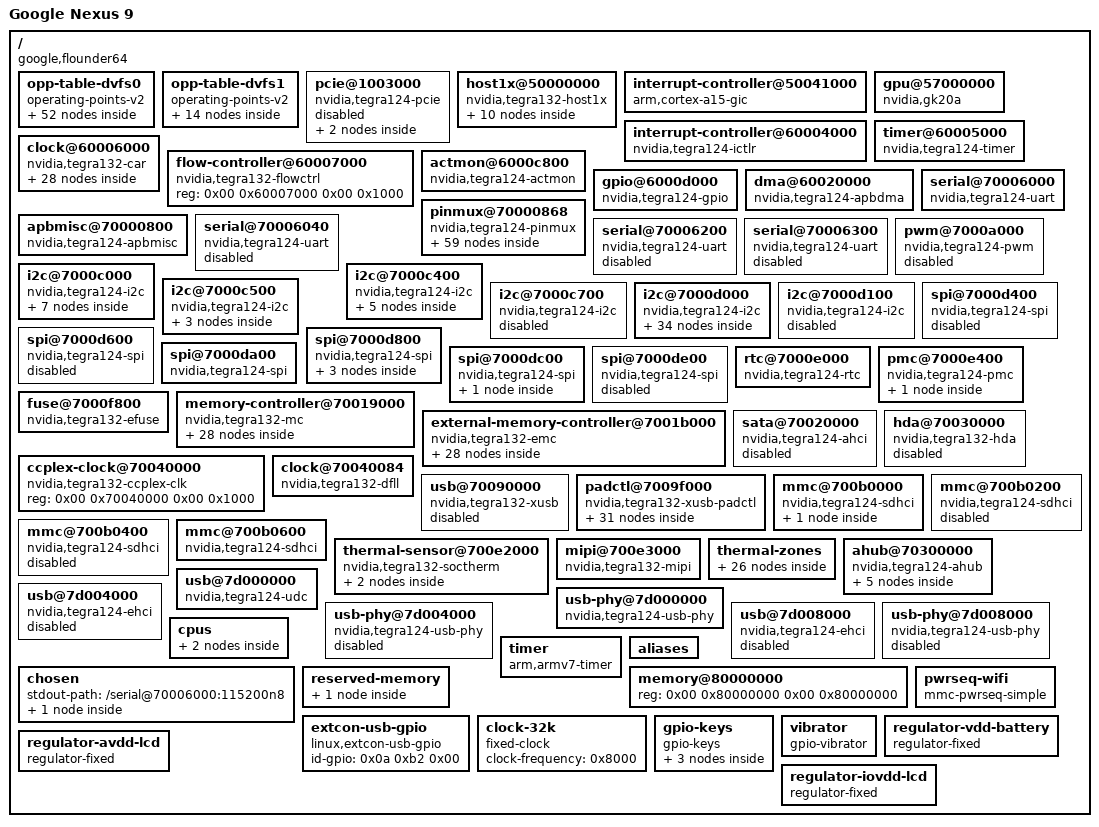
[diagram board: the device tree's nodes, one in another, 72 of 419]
/dts-v1/;

/ {
	compatible = "google,flounder64", "nvidia,tegra132";
	interrupt-parent = <0x01>;
	#address-cells = <0x02>;
	#size-cells = <0x02>;
	model = "Google Nexus 9";

	opp-table-dvfs0 {
		compatible = "operating-points-v2";
		phandle = <0x1a>;

		opp-12750000-800 {
			opp-microvolt = <0xc3500 0xc3500 0x118c30>;
			opp-hz = <0x00 0xc28cb0>;
			opp-supported-hw = <0x03>;
		};

		opp-12750000-950 {
			opp-microvolt = <0xe7ef0 0xe7ef0 0x118c30>;
			opp-hz = <0x00 0xc28cb0>;
			opp-supported-hw = <0x08>;
		};

		opp-12750000-1050 {
			opp-microvolt = <0x100590 0x100590 0x118c30>;
			opp-hz = <0x00 0xc28cb0>;
			opp-supported-hw = <0x10>;
		};

		opp-12750000-1110 {
			opp-microvolt = <0x10eff0 0x10eff0 0x118c30>;
			opp-hz = <0x00 0xc28cb0>;
			opp-supported-hw = <0x04>;
		};

		opp-20400000-800 {
			opp-microvolt = <0xc3500 0xc3500 0x118c30>;
			opp-hz = <0x00 0x1374780>;
			opp-supported-hw = <0x03>;
		};

		opp-20400000-950 {
			opp-microvolt = <0xe7ef0 0xe7ef0 0x118c30>;
			opp-hz = <0x00 0x1374780>;
			opp-supported-hw = <0x08>;
		};

		opp-20400000-1050 {
			opp-microvolt = <0x100590 0x100590 0x118c30>;
			opp-hz = <0x00 0x1374780>;
			opp-supported-hw = <0x10>;
		};

		opp-20400000-1110 {
			opp-microvolt = <0x10eff0 0x10eff0 0x118c30>;
			opp-hz = <0x00 0x1374780>;
			opp-supported-hw = <0x04>;
		};

		opp-40800000-800 {
			opp-microvolt = <0xc3500 0xc3500 0x118c30>;
			opp-hz = <0x00 0x26e8f00>;
			opp-supported-hw = <0x03>;
		};

		opp-40800000-950 {
			opp-microvolt = <0xe7ef0 0xe7ef0 0x118c30>;
			opp-hz = <0x00 0x26e8f00>;
			opp-supported-hw = <0x08>;
		};

		opp-40800000-1050 {
			opp-microvolt = <0x100590 0x100590 0x118c30>;
			opp-hz = <0x00 0x26e8f00>;
			opp-supported-hw = <0x10>;
		};

		opp-40800000-1110 {
			opp-microvolt = <0x10eff0 0x10eff0 0x118c30>;
			opp-hz = <0x00 0x26e8f00>;
			opp-supported-hw = <0x04>;
		};

		opp-68000000-800 {
			opp-microvolt = <0xc3500 0xc3500 0x118c30>;
			opp-hz = <0x00 0x40d9900>;
			opp-supported-hw = <0x03>;
		};

		opp-68000000-950 {
			opp-microvolt = <0xe7ef0 0xe7ef0 0x118c30>;
			opp-hz = <0x00 0x40d9900>;
			opp-supported-hw = <0x08>;
		};

		opp-68000000-1050 {
			opp-microvolt = <0x100590 0x100590 0x118c30>;
			opp-hz = <0x00 0x40d9900>;
			opp-supported-hw = <0x10>;
		};

		opp-68000000-1110 {
			opp-microvolt = <0x10eff0 0x10eff0 0x118c30>;
			opp-hz = <0x00 0x40d9900>;
			opp-supported-hw = <0x04>;
		};

		opp-102000000-800 {
			opp-microvolt = <0xc3500 0xc3500 0x118c30>;
			opp-hz = <0x00 0x6146580>;
			opp-supported-hw = <0x03>;
		};

		opp-102000000-950 {
			opp-microvolt = <0xe7ef0 0xe7ef0 0x118c30>;
			opp-hz = <0x00 0x6146580>;
			opp-supported-hw = <0x08>;
		};

		opp-102000000-1050 {
			opp-microvolt = <0x100590 0x100590 0x118c30>;
			opp-hz = <0x00 0x6146580>;
			opp-supported-hw = <0x10>;
		};

		opp-102000000-1110 {
			opp-microvolt = <0x10eff0 0x10eff0 0x118c30>;
			opp-hz = <0x00 0x6146580>;
			opp-supported-hw = <0x04>;
		};

		opp-204000000-800 {
			opp-microvolt = <0xc3500 0xc3500 0x118c30>;
			opp-hz = <0x00 0xc28cb00>;
			opp-supported-hw = <0x03>;
			opp-suspend;
		};

		opp-204000000-950 {
			opp-microvolt = <0xe7ef0 0xe7ef0 0x118c30>;
			opp-hz = <0x00 0xc28cb00>;
			opp-supported-hw = <0x08>;
			opp-suspend;
		};

		opp-204000000-1050 {
			opp-microvolt = <0x100590 0x100590 0x118c30>;
			opp-hz = <0x00 0xc28cb00>;
			opp-supported-hw = <0x10>;
			opp-suspend;
		};

		opp-204000000-1110 {
			opp-microvolt = <0x10eff0 0x10eff0 0x118c30>;
			opp-hz = <0x00 0xc28cb00>;
			opp-supported-hw = <0x04>;
			opp-suspend;
		};

		opp-264000000-800 {
			opp-microvolt = <0xc3500 0xc3500 0x118c30>;
			opp-hz = <0x00 0xfbc5200>;
			opp-supported-hw = <0x03>;
		};

		opp-264000000-950 {
			opp-microvolt = <0xe7ef0 0xe7ef0 0x118c30>;
			opp-hz = <0x00 0xfbc5200>;
			opp-supported-hw = <0x08>;
		};

		opp-264000000-1050 {
			opp-microvolt = <0x100590 0x100590 0x118c30>;
			opp-hz = <0x00 0xfbc5200>;
			opp-supported-hw = <0x10>;
		};

		opp-264000000-1110 {
			opp-microvolt = <0x10eff0 0x10eff0 0x118c30>;
			opp-hz = <0x00 0xfbc5200>;
			opp-supported-hw = <0x04>;
		};

		opp-300000000-850 {
			opp-microvolt = <0xcf850 0xcf850 0x118c30>;
			opp-hz = <0x00 0x11e1a300>;
			opp-supported-hw = <0x03>;
		};

		opp-300000000-950 {
			opp-microvolt = <0xe7ef0 0xe7ef0 0x118c30>;
			opp-hz = <0x00 0x11e1a300>;
			opp-supported-hw = <0x08>;
		};

		opp-300000000-1050 {
			opp-microvolt = <0x100590 0x100590 0x118c30>;
			opp-hz = <0x00 0x11e1a300>;
			opp-supported-hw = <0x10>;
		};

		opp-300000000-1110 {
			opp-microvolt = <0x10eff0 0x10eff0 0x118c30>;
			opp-hz = <0x00 0x11e1a300>;
			opp-supported-hw = <0x04>;
		};

		opp-348000000-850 {
			opp-microvolt = <0xcf850 0xcf850 0x118c30>;
			opp-hz = <0x00 0x14be0f00>;
			opp-supported-hw = <0x03>;
		};

		opp-348000000-950 {
			opp-microvolt = <0xe7ef0 0xe7ef0 0x118c30>;
			opp-hz = <0x00 0x14be0f00>;
			opp-supported-hw = <0x08>;
		};

		opp-348000000-1050 {
			opp-microvolt = <0x100590 0x100590 0x118c30>;
			opp-hz = <0x00 0x14be0f00>;
			opp-supported-hw = <0x10>;
		};

		opp-348000000-1110 {
			opp-microvolt = <0x10eff0 0x10eff0 0x118c30>;
			opp-hz = <0x00 0x14be0f00>;
			opp-supported-hw = <0x04>;
		};

		opp-396000000-950 {
			opp-microvolt = <0xe7ef0 0xe7ef0 0x118c30>;
			opp-hz = <0x00 0x179a7b00>;
			opp-supported-hw = <0x08>;
		};

		opp-396000000-1000 {
			opp-microvolt = <0xf4240 0xf4240 0x118c30>;
			opp-hz = <0x00 0x179a7b00>;
			opp-supported-hw = <0x03>;
		};

		opp-396000000-1050 {
			opp-microvolt = <0x100590 0x100590 0x118c30>;
			opp-hz = <0x00 0x179a7b00>;
			opp-supported-hw = <0x10>;
		};

		opp-396000000-1110 {
			opp-microvolt = <0x10eff0 0x10eff0 0x118c30>;
			opp-hz = <0x00 0x179a7b00>;
			opp-supported-hw = <0x04>;
		};

		opp-528000000-950 {
			opp-microvolt = <0xe7ef0 0xe7ef0 0x118c30>;
			opp-hz = <0x00 0x1f78a400>;
			opp-supported-hw = <0x08>;
		};

		opp-528000000-1000 {
			opp-microvolt = <0xf4240 0xf4240 0x118c30>;
			opp-hz = <0x00 0x1f78a400>;
			opp-supported-hw = <0x03>;
		};

		opp-528000000-1050 {
			opp-microvolt = <0x100590 0x100590 0x118c30>;
			opp-hz = <0x00 0x1f78a400>;
			opp-supported-hw = <0x10>;
		};

		opp-528000000-1110 {
			opp-microvolt = <0x10eff0 0x10eff0 0x118c30>;
			opp-hz = <0x00 0x1f78a400>;
			opp-supported-hw = <0x04>;
		};

		opp-600000000-950 {
			opp-microvolt = <0xe7ef0 0xe7ef0 0x118c30>;
			opp-hz = <0x00 0x23c34600>;
			opp-supported-hw = <0x08>;
		};

		opp-600000000-1000 {
			opp-microvolt = <0xf4240 0xf4240 0x118c30>;
			opp-hz = <0x00 0x23c34600>;
			opp-supported-hw = <0x03>;
		};

		opp-600000000-1050 {
			opp-microvolt = <0x100590 0x100590 0x118c30>;
			opp-hz = <0x00 0x23c34600>;
			opp-supported-hw = <0x10>;
		};

		opp-600000000-1110 {
			opp-microvolt = <0x10eff0 0x10eff0 0x118c30>;
			opp-hz = <0x00 0x23c34600>;
			opp-supported-hw = <0x04>;
		};

		opp-792000000-1000 {
			opp-microvolt = <0xf4240 0xf4240 0x118c30>;
			opp-hz = <0x00 0x2f34f600>;
			opp-supported-hw = <0x0b>;
		};

		opp-792000000-1050 {
			opp-microvolt = <0x100590 0x100590 0x118c30>;
			opp-hz = <0x00 0x2f34f600>;
			opp-supported-hw = <0x10>;
		};

		opp-792000000-1110 {
			opp-microvolt = <0x10eff0 0x10eff0 0x118c30>;
			opp-hz = <0x00 0x2f34f600>;
			opp-supported-hw = <0x04>;
		};

		opp-924000000-1100 {
			opp-microvolt = <0x10c8e0 0x10c8e0 0x118c30>;
			opp-hz = <0x00 0x37131f00>;
			opp-supported-hw = <0x13>;
		};
	};

	opp-table-dvfs1 {
		compatible = "operating-points-v2";
		phandle = <0x0f>;

		opp-12750000 {
			opp-hz = <0x00 0xc28cb0>;
			opp-supported-hw = <0x1f>;
			opp-peak-kBps = <0x31ce0>;
		};

		opp-20400000 {
			opp-hz = <0x00 0x1374780>;
			opp-supported-hw = <0x1f>;
			opp-peak-kBps = <0x4fb00>;
		};

		opp-40800000 {
			opp-hz = <0x00 0x26e8f00>;
			opp-supported-hw = <0x1f>;
			opp-peak-kBps = <0x9f600>;
		};

		opp-68000000 {
			opp-hz = <0x00 0x40d9900>;
			opp-supported-hw = <0x1f>;
			opp-peak-kBps = <0x109a00>;
		};

		opp-102000000 {
			opp-hz = <0x00 0x6146580>;
			opp-supported-hw = <0x1f>;
			opp-peak-kBps = <0x18e700>;
		};

		opp-204000000 {
			opp-hz = <0x00 0xc28cb00>;
			opp-supported-hw = <0x1f>;
			opp-peak-kBps = <0x31ce00>;
			opp-suspend;
		};

		opp-264000000 {
			opp-hz = <0x00 0xfbc5200>;
			opp-supported-hw = <0x1f>;
			opp-peak-kBps = "", "@t";
		};

		opp-300000000 {
			opp-hz = <0x00 0x11e1a300>;
			opp-supported-hw = <0x1f>;
			opp-peak-kBps = "", "I>";
		};

		opp-348000000 {
			opp-hz = <0x00 0x14be0f00>;
			opp-supported-hw = <0x1f>;
			opp-peak-kBps = <0x54f600>;
		};

		opp-396000000 {
			opp-hz = <0x00 0x179a7b00>;
			opp-supported-hw = <0x1f>;
			opp-peak-kBps = <0x60ae00>;
		};

		opp-528000000 {
			opp-hz = <0x00 0x1f78a400>;
			opp-supported-hw = <0x1f>;
			opp-peak-kBps = <0x80e800>;
		};

		opp-600000000 {
			opp-hz = <0x00 0x23c34600>;
			opp-supported-hw = <0x1f>;
			opp-peak-kBps = <0x927c00>;
		};

		opp-792000000 {
			opp-hz = <0x00 0x2f34f600>;
			opp-supported-hw = <0x1f>;
			opp-peak-kBps = <0xc15c00>;
		};

		opp-924000000 {
			opp-hz = <0x00 0x37131f00>;
			opp-supported-hw = <0x13>;
			opp-peak-kBps = <0xe19600>;
		};
	};

	pcie@1003000 {
		compatible = "nvidia,tegra124-pcie";
		device_type = "pci";
		reg = <0x00 0x1003000 0x00 0x800 0x00 0x1003800 0x00 0x800 0x00 0x2000000 0x00 0x10000000>;
		reg-names = "pads", "afi", "cs";
		interrupts = <0x00 0x62 0x04 0x00 0x63 0x04>;
		interrupt-names = "intr", "msi";
		#interrupt-cells = <0x01>;
		interrupt-map-mask = <0x00 0x00 0x00 0x00>;
		interrupt-map = <0x00 0x00 0x00 0x00 0x02 0x00 0x62 0x04>;
		bus-range = <0x00 0xff>;
		#address-cells = <0x03>;
		#size-cells = <0x02>;
		ranges = <0x2000000 0x00 0x1000000 0x00 0x1000000 0x00 0x1000 0x2000000 0x00 0x1001000 0x00 0x1001000 0x00 0x1000 0x1000000 0x00 0x00 0x00 0x12000000 0x00 0x10000 0x2000000 0x00 0x13000000 0x00 0x13000000 0x00 0xd000000 0x42000000 0x00 0x20000000 0x00 0x20000000 0x00 0x20000000>;
		clocks = <0x03 0x46 0x03 0x48 0x03 0xe7 0x03 0x10c>;
		clock-names = "pex", "afi", "pll_e", "cml";
		resets = <0x03 0x46 0x03 0x48 0x03 0x4a>;
		reset-names = "pex", "afi", "pcie_x";
		status = "disabled";

		pci@1,0 {
			device_type = "pci";
			assigned-addresses = <0x82000800 0x00 0x1000000 0x00 0x1000>;
			reg = <0x800 0x00 0x00 0x00 0x00>;
			bus-range = <0x00 0xff>;
			status = "disabled";
			#address-cells = <0x03>;
			#size-cells = <0x02>;
			ranges;
			nvidia,num-lanes = <0x02>;
		};

		pci@2,0 {
			device_type = "pci";
			assigned-addresses = <0x82001000 0x00 0x1001000 0x00 0x1000>;
			reg = <0x1000 0x00 0x00 0x00 0x00>;
			bus-range = <0x00 0xff>;
			status = "disabled";
			#address-cells = <0x03>;
			#size-cells = <0x02>;
			ranges;
			nvidia,num-lanes = <0x01>;
		};
	};

	host1x@50000000 {
		compatible = "nvidia,tegra132-host1x", "nvidia,tegra124-host1x";
		reg = <0x00 0x50000000 0x00 0x34000>;
		interrupts = <0x00 0x41 0x04 0x00 0x43 0x04>;
		interrupt-names = "syncpt", "host1x";
		clocks = <0x03 0x1c>;
		clock-names = "host1x";
		resets = <0x03 0x1c>;
		reset-names = "host1x";
		#address-cells = <0x02>;
		#size-cells = <0x02>;
		ranges = <0x00 0x54000000 0x00 0x54000000 0x00 0x1000000>;

		dc@54200000 {
			compatible = "nvidia,tegra124-dc";
			reg = <0x00 0x54200000 0x00 0x40000>;
			interrupts = <0x00 0x49 0x04>;
			clocks = <0x03 0x1b>;
			clock-names = "dc";
			resets = <0x03 0x1b>;
			reset-names = "dc";
			iommus = <0x04 0x01>;
			nvidia,head = <0x00>;
		};

		dc@54240000 {
			compatible = "nvidia,tegra124-dc";
			reg = <0x00 0x54240000 0x00 0x40000>;
			interrupts = <0x00 0x4a 0x04>;
			clocks = <0x03 0x1a>;
			clock-names = "dc";
			resets = <0x03 0x1a>;
			reset-names = "dc";
			iommus = <0x04 0x02>;
			nvidia,head = <0x01>;
		};

		hdmi@54280000 {
			compatible = "nvidia,tegra124-hdmi";
			reg = <0x00 0x54280000 0x00 0x40000>;
			interrupts = <0x00 0x4b 0x04>;
			clocks = <0x03 0x33 0x03 0xdd>;
			clock-names = "hdmi", "parent";
			resets = <0x03 0x33>;
			reset-names = "hdmi";
			status = "disabled";
		};

		dsi@54300000 {
			compatible = "nvidia,tegra132-dsi";
			reg = <0x00 0x54300000 0x00 0x40000>;
			clocks = <0x03 0x30 0x03 0x93 0x03 0xdb>;
			clock-names = "dsi", "lp", "parent";
			resets = <0x03 0x30>;
			reset-names = "dsi";
			nvidia,mipi-calibrate = <0x05 0x60>;
			status = "okay";
			#address-cells = <0x01>;
			#size-cells = <0x00>;
			avdd-dsi-csi-supply = <0x06>;
			nvidia,ganged-mode = <0x07>;

			panel@0 {
				compatible = "jdi,lpm089a128a";
				reg = <0x00>;
				avdd-supply = <0x08>;
				iovdd-supply = <0x09>;
				reset-gpios = <0x0a 0x3d 0x00>;
				dcdc-en-gpios = <0x0a 0xf5 0x00>;
				port_b = <0x0b>;
				phandle = <0x0c>;
			};
		};

		dsi@54400000 {
			compatible = "nvidia,tegra132-dsi";
			reg = <0x00 0x54400000 0x00 0x40000>;
			clocks = <0x03 0x52 0x03 0x94 0x03 0xdb>;
			clock-names = "dsi", "lp", "parent";
			resets = <0x03 0x52>;
			reset-names = "dsi";
			nvidia,mipi-calibrate = <0x05 0x180>;
			status = "okay";
			#address-cells = <0x01>;
			#size-cells = <0x00>;
			avdd-dsi-csi-supply = <0x06>;
			phandle = <0x07>;

			panel@0 {
				compatible = "jdi,lpm089a128a";
				reg = <0x00>;
				port_a = <0x0c>;
				phandle = <0x0b>;
			};
		};

		sor@54540000 {
			compatible = "nvidia,tegra124-sor";
			reg = <0x00 0x54540000 0x00 0x40000>;
			interrupts = <0x00 0x4c 0x04>;
			clocks = <0x03 0xb6 0x03 0x137 0x03 0xdb 0x03 0x10f 0x03 0xc9>;
			clock-names = "sor", "out", "parent", "dp", "safe";
			resets = <0x03 0xb6>;
			reset-names = "sor";
			status = "disabled";
		};

		dpaux@545c0000 {
			compatible = "nvidia,tegra124-dpaux";
			reg = <0x00 0x545c0000 0x00 0x40000>;
			interrupts = <0x00 0x9f 0x04>;
			clocks = <0x03 0xb5 0x03 0x10f>;
			clock-names = "dpaux", "parent";
			resets = <0x03 0xb5>;
			reset-names = "dpaux";
			status = "disabled";

			i2c-bus {
				#address-cells = <0x01>;
				#size-cells = <0x00>;
			};
		};
	};

	interrupt-controller@50041000 {
		compatible = "arm,cortex-a15-gic";
		#interrupt-cells = <0x03>;
		interrupt-controller;
		reg = <0x00 0x50041000 0x00 0x1000 0x00 0x50042000 0x00 0x2000 0x00 0x50044000 0x00 0x2000 0x00 0x50046000 0x00 0x2000>;
		interrupts = <0x01 0x09 0xf04>;
		interrupt-parent = <0x02>;
		phandle = <0x02>;
	};

	gpu@57000000 {
		compatible = "nvidia,gk20a";
		reg = <0x00 0x57000000 0x00 0x1000000 0x00 0x58000000 0x00 0x1000000>;
		interrupts = <0x00 0x9d 0x04 0x00 0x9e 0x04>;
		interrupt-names = "stall", "nonstall";
		clocks = <0x03 0xb8 0x03 0x10b>;
		clock-names = "gpu", "pwr";
		resets = <0x03 0xb8>;
		reset-names = "gpu";
		status = "okay";
		vdd-supply = <0x0d>;
	};

	interrupt-controller@60004000 {
		compatible = "nvidia,tegra124-ictlr", "nvidia,tegra30-ictlr";
		reg = <0x00 0x60004000 0x00 0x100 0x00 0x60004100 0x00 0x100 0x00 0x60004200 0x00 0x100 0x00 0x60004300 0x00 0x100 0x00 0x60004400 0x00 0x100>;
		interrupt-controller;
		#interrupt-cells = <0x03>;
		interrupt-parent = <0x02>;
		phandle = <0x01>;
	};

	timer@60005000 {
		compatible = "nvidia,tegra124-timer", "nvidia,tegra30-timer";
		reg = <0x00 0x60005000 0x00 0x400>;
		interrupts = <0x00 0x00 0x04 0x00 0x01 0x04 0x00 0x29 0x04 0x00 0x2a 0x04 0x00 0x79 0x04 0x00 0x7a 0x04>;
		clocks = <0x03 0x05>;
		clock-names = "timer";
	};

	clock@60006000 {
		compatible = "nvidia,tegra132-car";
		reg = <0x00 0x60006000 0x00 0x1000>;
		#clock-cells = <0x01>;
		#reset-cells = <0x01>;
		nvidia,external-memory-controller = <0x0e>;
		phandle = <0x03>;

		emc-timings-1 {
			nvidia,ram-code = <0x01>;

			timing-12750000 {
				clock-frequency = <0xc28cb0>;
				nvidia,parent-clock-frequency = <0x18519600>;
				clocks = <0x03 0xd3>;
				clock-names = "emc-parent";
			};

			timing-20400000 {
				clock-frequency = <0x1374780>;
				nvidia,parent-clock-frequency = <0x18519600>;
				clocks = <0x03 0xd3>;
				clock-names = "emc-parent";
			};

			timing-40800000 {
				clock-frequency = <0x26e8f00>;
				nvidia,parent-clock-frequency = <0x18519600>;
				clocks = <0x03 0xd3>;
				clock-names = "emc-parent";
			};

			timing-68000000 {
				clock-frequency = <0x40d9900>;
				nvidia,parent-clock-frequency = <0x18519600>;
				clocks = <0x03 0xd3>;
				clock-names = "emc-parent";
			};

			timing-102000000 {
				clock-frequency = <0x6146580>;
				nvidia,parent-clock-frequency = <0x18519600>;
				clocks = <0x03 0xd3>;
				clock-names = "emc-parent";
			};

			timing-136000000 {
				clock-frequency = <0x81b3200>;
				nvidia,parent-clock-frequency = <0x18519600>;
				clocks = <0x03 0xd3>;
				clock-names = "emc-parent";
			};

			timing-204000000 {
				clock-frequency = <0xc28cb00>;
				nvidia,parent-clock-frequency = <0x18519600>;
				clocks = <0x03 0xd3>;
				clock-names = "emc-parent";
			};

			timing-300000000 {
				clock-frequency = <0x11e1a300>;
				nvidia,parent-clock-frequency = <0x23c34600>;
				clocks = <0x03 0xcd>;
				clock-names = "emc-parent";
			};

			timing-396000000 {
				clock-frequency = <0x179a7b00>;
				nvidia,parent-clock-frequency = <0x2f34f600>;
				clocks = <0x03 0xd1>;
				clock-names = "emc-parent";
			};

			timing-528000000 {
				clock-frequency = <0x1f78a400>;
				nvidia,parent-clock-frequency = <0x1f78a400>;
				clocks = <0x03 0x139>;
				clock-names = "emc-parent";
			};

			timing-600000000 {
				clock-frequency = <0x23c34600>;
				nvidia,parent-clock-frequency = <0x23c34600>;
				clocks = <0x03 0x13a>;
				clock-names = "emc-parent";
			};

			timing-792000000 {
				clock-frequency = <0x2f34f600>;
				nvidia,parent-clock-frequency = <0x2f34f600>;
				clocks = <0x03 0x139>;
				clock-names = "emc-parent";
			};

			timing-924000000 {
				clock-frequency = <0x37131f00>;
				nvidia,parent-clock-frequency = <0x37131f00>;
				clocks = <0x03 0x139>;
				clock-names = "emc-parent";
			};
		};

		emc-timings-2 {
			nvidia,ram-code = <0x02>;

			timing-12750000 {
				clock-frequency = <0xc28cb0>;
				nvidia,parent-clock-frequency = <0x18519600>;
				clocks = <0x03 0xd3>;
				clock-names = "emc-parent";
			};

			timing-20400000 {
				clock-frequency = <0x1374780>;
				nvidia,parent-clock-frequency = <0x18519600>;
				clocks = <0x03 0xd3>;
				clock-names = "emc-parent";
			};

			timing-40800000 {
				clock-frequency = <0x26e8f00>;
				nvidia,parent-clock-frequency = <0x18519600>;
				clocks = <0x03 0xd3>;
				clock-names = "emc-parent";
			};

			timing-68000000 {
				clock-frequency = <0x40d9900>;
				nvidia,parent-clock-frequency = <0x18519600>;
				clocks = <0x03 0xd3>;
				clock-names = "emc-parent";
			};

			timing-102000000 {
				clock-frequency = <0x6146580>;
				nvidia,parent-clock-frequency = <0x18519600>;
				clocks = <0x03 0xd3>;
				clock-names = "emc-parent";
			};

			timing-136000000 {
				clock-frequency = <0x81b3200>;
				nvidia,parent-clock-frequency = <0x18519600>;
				clocks = <0x03 0xd3>;
				clock-names = "emc-parent";
			};

			timing-204000000 {
				clock-frequency = <0xc28cb00>;
				nvidia,parent-clock-frequency = <0x18519600>;
				clocks = <0x03 0xd3>;
				clock-names = "emc-parent";
			};

			timing-300000000 {
				clock-frequency = <0x11e1a300>;
				nvidia,parent-clock-frequency = <0x23c34600>;
				clocks = <0x03 0xcd>;
				clock-names = "emc-parent";
			};

			timing-396000000 {
				clock-frequency = <0x179a7b00>;
				nvidia,parent-clock-frequency = <0x2f34f600>;
				clocks = <0x03 0xd1>;
				clock-names = "emc-parent";
			};

			timing-528000000 {
				clock-frequency = <0x1f78a400>;
				nvidia,parent-clock-frequency = <0x1f78a400>;
				clocks = <0x03 0x139>;
				clock-names = "emc-parent";
			};

			timing-600000000 {
				clock-frequency = <0x23c34600>;
				nvidia,parent-clock-frequency = <0x23c34600>;
				clocks = <0x03 0x13a>;
				clock-names = "emc-parent";
			};

			timing-792000000 {
				clock-frequency = <0x2f34f600>;
				nvidia,parent-clock-frequency = <0x2f34f600>;
				clocks = <0x03 0x139>;
				clock-names = "emc-parent";
			};

			timing-924000000 {
				clock-frequency = <0x37131f00>;
				nvidia,parent-clock-frequency = <0x37131f00>;
				clocks = <0x03 0x139>;
				clock-names = "emc-parent";
			};
		};
	};

	flow-controller@60007000 {
		compatible = "nvidia,tegra132-flowctrl", "nvidia,tegra124-flowctrl";
		reg = <0x00 0x60007000 0x00 0x1000>;
	};

	actmon@6000c800 {
		compatible = "nvidia,tegra124-actmon";
		reg = <0x00 0x6000c800 0x00 0x400>;
		interrupts = <0x00 0x2d 0x04>;
		clocks = <0x03 0x77 0x03 0x39>;
		clock-names = "actmon", "emc";
		resets = <0x03 0x77>;
		reset-names = "actmon";
		operating-points-v2 = <0x0f>;
		interconnects = <0x04 0x27 0x0e>;
		interconnect-names = "cpu-read";
		#cooling-cells = <0x02>;
	};

	gpio@6000d000 {
		compatible = "nvidia,tegra124-gpio", "nvidia,tegra30-gpio";
		reg = <0x00 0x6000d000 0x00 0x1000>;
		interrupts = <0x00 0x20 0x04 0x00 0x21 0x04 0x00 0x22 0x04 0x00 0x23 0x04 0x00 0x37 0x04 0x00 0x57 0x04 0x00 0x59 0x04 0x00 0x7d 0x04>;
		#gpio-cells = <0x02>;
		gpio-controller;
		#interrupt-cells = <0x02>;
		interrupt-controller;
		phandle = <0x0a>;
	};

	dma@60020000 {
		compatible = "nvidia,tegra124-apbdma", "nvidia,tegra148-apbdma";
		reg = <0x00 0x60020000 0x00 0x1400>;
		interrupts = <0x00 0x68 0x04 0x00 0x69 0x04 0x00 0x6a 0x04 0x00 0x6b 0x04 0x00 0x6c 0x04 0x00 0x6d 0x04 0x00 0x6e 0x04 0x00 0x6f 0x04 0x00 0x70 0x04 0x00 0x71 0x04 0x00 0x72 0x04 0x00 0x73 0x04 0x00 0x74 0x04 0x00 0x75 0x04 0x00 0x76 0x04 0x00 0x77 0x04 0x00 0x80 0x04 0x00 0x81 0x04 0x00 0x82 0x04 0x00 0x83 0x04 0x00 0x84 0x04 0x00 0x85 0x04 0x00 0x86 0x04 0x00 0x87 0x04 0x00 0x88 0x04 0x00 0x89 0x04 0x00 0x8a 0x04 0x00 0x8b 0x04 0x00 0x8c 0x04 0x00 0x8d 0x04 0x00 0x8e 0x04 0x00 0x8f 0x04>;
		clocks = <0x03 0x22>;
		clock-names = "dma";
		resets = <0x03 0x22>;
		reset-names = "dma";
		#dma-cells = <0x01>;
		phandle = <0x11>;
	};

	apbmisc@70000800 {
		compatible = "nvidia,tegra124-apbmisc", "nvidia,tegra20-apbmisc";
		reg = <0x00 0x70000800 0x00 0x64 0x00 0x7000e864 0x00 0x04>;
		nvidia,long-ram-code;
	};

	pinmux@70000868 {
		compatible = "nvidia,tegra124-pinmux";
		reg = <0x00 0x70000868 0x00 0x164 0x00 0x70003000 0x00 0x434 0x00 0x70000820 0x00 0x08>;
		pinctrl-names = "default";
		pinctrl-0 = <0x10>;

		pinmux {
			phandle = <0x10>;

			pu0 {
				nvidia,pins = "pu0";
				nvidia,function = "uarta";
				nvidia,pull = <0x00>;
				nvidia,tristate = <0x00>;
				nvidia,enable-input = <0x00>;
			};

			pu1 {
				nvidia,pins = "pu1";
				nvidia,function = "uarta";
				nvidia,pull = <0x02>;
				nvidia,tristate = <0x00>;
				nvidia,enable-input = <0x01>;
			};

			uart3_cts_n_pa1 {
				nvidia,pins = "uart3_cts_n_pa1", "uart3_rxd_pw7";
				nvidia,function = "uartc";
				nvidia,pull = <0x02>;
				nvidia,tristate = <0x00>;
				nvidia,enable-input = <0x01>;
			};

			uart3_rts_n_pc0 {
				nvidia,pins = "uart3_rts_n_pc0", "uart3_txd_pw6";
				nvidia,function = "uartc";
				nvidia,pull = <0x00>;
				nvidia,tristate = <0x00>;
				nvidia,enable-input = <0x00>;
			};

			pj7 {
				nvidia,pins = "pj7";
				nvidia,function = "uartd";
				nvidia,pull = <0x00>;
				nvidia,tristate = <0x00>;
				nvidia,enable-input = <0x00>;
			};

			pb0 {
				nvidia,pins = "pb0";
				nvidia,function = "uartd";
				nvidia,pull = <0x00>;
				nvidia,tristate = <0x00>;
				nvidia,enable-input = <0x01>;
			};

			ph0 {
				nvidia,pins = "ph0";
				nvidia,function = "dtv";
				nvidia,pull = <0x01>;
				nvidia,tristate = <0x01>;
				nvidia,enable-input = <0x01>;
			};

			ph1 {
				nvidia,pins = "ph1";
				nvidia,function = "pwm1";
				nvidia,pull = <0x00>;
				nvidia,tristate = <0x00>;
				nvidia,enable-input = <0x00>;
			};

			gen1_i2c_scl_pc4 {
				nvidia,pins = "gen1_i2c_scl_pc4", "gen1_i2c_sda_pc5";
				nvidia,function = "i2c1";
				nvidia,pull = <0x00>;
				nvidia,tristate = <0x00>;
				nvidia,enable-input = <0x01>;
				nvidia,lock = <0x00>;
				nvidia,open-drain = <0x00>;
			};

			gen2_i2c_scl_pt5 {
				nvidia,pins = "gen2_i2c_scl_pt5", "gen2_i2c_sda_pt6";
				nvidia,function = "i2c2";
				nvidia,pull = <0x00>;
				nvidia,tristate = <0x00>;
				nvidia,enable-input = <0x01>;
				nvidia,lock = <0x00>;
				nvidia,open-drain = <0x00>;
			};

			cam_i2c_scl_pbb1 {
				nvidia,pins = "cam_i2c_scl_pbb1", "cam_i2c_sda_pbb2";
				nvidia,function = "i2c3";
				nvidia,pull = <0x00>;
				nvidia,tristate = <0x00>;
				nvidia,enable-input = <0x01>;
				nvidia,lock = <0x00>;
				nvidia,open-drain = <0x00>;
			};

			pwr_i2c_scl_pz6 {
				nvidia,pins = "pwr_i2c_scl_pz6", "pwr_i2c_sda_pz7";
				nvidia,function = "i2cpwr";
				nvidia,pull = <0x00>;
				nvidia,tristate = <0x00>;
				nvidia,enable-input = <0x01>;
				nvidia,lock = <0x00>;
				nvidia,open-drain = <0x00>;
			};

			sdmmc3_clk_pa6 {
				nvidia,pins = "sdmmc3_clk_pa6", "sdmmc3_dat1_pb6", "sdmmc3_dat2_pb5", "sdmmc3_dat3_pb4";
				nvidia,function = "spi3";
				nvidia,pull = <0x00>;
				nvidia,tristate = <0x00>;
				nvidia,enable-input = <0x01>;
			};

			sdmmc3_dat0_pb7 {
				nvidia,pins = "sdmmc3_dat0_pb7";
				nvidia,function = "spi3";
				nvidia,pull = <0x02>;
				nvidia,tristate = <0x00>;
				nvidia,enable-input = <0x01>;
			};

			pg4 {
				nvidia,pins = "pg4", "pg5", "pg6";
				nvidia,function = "spi4";
				nvidia,pull = <0x00>;
				nvidia,tristate = <0x00>;
				nvidia,enable-input = <0x00>;
			};

			pg7 {
				nvidia,pins = "pg7";
				nvidia,function = "spi4";
				nvidia,pull = <0x00>;
				nvidia,tristate = <0x00>;
				nvidia,enable-input = <0x01>;
			};

			ulpi_clk_py0 {
				nvidia,pins = "ulpi_clk_py0", "ulpi_nxt_py2", "ulpi_stp_py3";
				nvidia,function = "spi5";
				nvidia,pull = <0x00>;
				nvidia,tristate = <0x00>;
				nvidia,enable-input = <0x00>;
			};

			ulpi_dir_py1 {
				nvidia,pins = "ulpi_dir_py1";
				nvidia,function = "spi5";
				nvidia,pull = <0x00>;
				nvidia,tristate = <0x00>;
				nvidia,enable-input = <0x01>;
			};

			sdmmc1_clk_pz0 {
				nvidia,pins = "sdmmc1_clk_pz0";
				nvidia,function = "sdmmc1";
				nvidia,pull = <0x00>;
				nvidia,tristate = <0x00>;
				nvidia,enable-input = <0x01>;
			};

			sdmmc1_cmd_pz1 {
				nvidia,pins = "sdmmc1_cmd_pz1", "sdmmc1_dat0_py7", "sdmmc1_dat1_py6", "sdmmc1_dat2_py5", "sdmmc1_dat3_py4";
				nvidia,function = "sdmmc1";
				nvidia,pull = <0x02>;
				nvidia,tristate = <0x00>;
				nvidia,enable-input = <0x01>;
			};

			sdmmc4_clk_pcc4 {
				nvidia,pins = "sdmmc4_clk_pcc4";
				nvidia,function = "sdmmc4";
				nvidia,pull = <0x00>;
				nvidia,tristate = <0x00>;
				nvidia,enable-input = <0x01>;
			};

			sdmmc4_cmd_pt7 {
				nvidia,pins = "sdmmc4_cmd_pt7", "sdmmc4_dat0_paa0", "sdmmc4_dat1_paa1", "sdmmc4_dat2_paa2", "sdmmc4_dat3_paa3", "sdmmc4_dat4_paa4", "sdmmc4_dat5_paa5", "sdmmc4_dat6_paa6", "sdmmc4_dat7_paa7";
				nvidia,function = "sdmmc4";
				nvidia,pull = <0x02>;
				nvidia,tristate = <0x00>;
				nvidia,enable-input = <0x01>;
			};

			sdmmc3_cmd_pa7 {
				nvidia,pins = "sdmmc3_cmd_pa7";
				nvidia,pull = <0x01>;
				nvidia,tristate = <0x00>;
				nvidia,enable-input = <0x01>;
			};

			dap1_din_pn1 {
				nvidia,pins = "dap1_din_pn1";
				nvidia,function = "i2s0";
				nvidia,pull = <0x00>;
				nvidia,tristate = <0x01>;
				nvidia,enable-input = <0x01>;
			};

			dap1_dout_pn2 {
				nvidia,pins = "dap1_dout_pn2", "dap1_fs_pn0", "dap1_sclk_pn3";
				nvidia,function = "i2s0";
				nvidia,pull = <0x00>;
				nvidia,tristate = <0x01>;
				nvidia,enable-input = <0x00>;
			};

			dap2_din_pa4 {
				nvidia,pins = "dap2_din_pa4";
				nvidia,function = "i2s1";
				nvidia,pull = <0x00>;
				nvidia,tristate = <0x01>;
				nvidia,enable-input = <0x01>;
			};

			dap2_dout_pa5 {
				nvidia,pins = "dap2_dout_pa5", "dap2_fs_pa2", "dap2_sclk_pa3";
				nvidia,function = "i2s1";
				nvidia,pull = <0x00>;
				nvidia,tristate = <0x01>;
				nvidia,enable-input = <0x00>;
			};

			dap3_din_pp1 {
				nvidia,pins = "dap3_din_pp1";
				nvidia,function = "i2s2";
				nvidia,pull = <0x00>;
				nvidia,tristate = <0x01>;
				nvidia,enable-input = <0x01>;
			};

			dap3_dout_pp2 {
				nvidia,pins = "dap3_dout_pp2", "dap3_fs_pp0", "dap3_sclk_pp3";
				nvidia,function = "i2s2";
				nvidia,pull = <0x00>;
				nvidia,tristate = <0x01>;
				nvidia,enable-input = <0x00>;
			};

			dap4_din_pp5 {
				nvidia,pins = "dap4_din_pp5";
				nvidia,function = "i2s3";
				nvidia,pull = <0x00>;
				nvidia,tristate = <0x01>;
				nvidia,enable-input = <0x01>;
			};

			dap4_dout_pp6 {
				nvidia,pins = "dap4_dout_pp6", "dap4_fs_pp4", "dap4_sclk_pp7";
				nvidia,function = "i2s3";
				nvidia,pull = <0x00>;
				nvidia,tristate = <0x01>;
				nvidia,enable-input = <0x00>;
			};

			cam_mclk_pcc0 {
				nvidia,pins = "cam_mclk_pcc0";
				nvidia,function = "vi_alt3";
				nvidia,pull = <0x00>;
				nvidia,tristate = <0x00>;
				nvidia,enable-input = <0x00>;
				nvidia,lock = <0x00>;
			};

			pbb0 {
				nvidia,pins = "pbb0";
				nvidia,function = "vimclk2_alt";
				nvidia,pull = <0x00>;
				nvidia,tristate = <0x00>;
				nvidia,enable-input = <0x00>;
				nvidia,lock = <0x00>;
			};

			pj2 {
				nvidia,pins = "pj2", "clk_32k_out_pa0";
				nvidia,function = "soc";
				nvidia,pull = <0x02>;
				nvidia,tristate = <0x00>;
				nvidia,enable-input = <0x01>;
			};

			dap_mclk1_pw4 {
				nvidia,pins = "dap_mclk1_pw4";
				nvidia,function = "extperiph1";
				nvidia,pull = <0x00>;
				nvidia,tristate = <0x00>;
				nvidia,enable-input = <0x00>;
			};

			clk2_out_pw5 {
				nvidia,pins = "clk2_out_pw5";
				nvidia,function = "extperiph2";
				nvidia,pull = <0x00>;
				nvidia,tristate = <0x00>;
				nvidia,enable-input = <0x00>;
			};

			clk3_out_pee0 {
				nvidia,pins = "clk3_out_pee0";
				nvidia,function = "extperiph3";
				nvidia,pull = <0x00>;
				nvidia,tristate = <0x00>;
				nvidia,enable-input = <0x00>;
			};

			jtag_rtck {
				nvidia,pins = "jtag_rtck";
				nvidia,function = "rtck";
				nvidia,pull = <0x02>;
				nvidia,tristate = <0x00>;
				nvidia,enable-input = <0x00>;
			};

			clk_32k_in {
				nvidia,pins = "clk_32k_in";
				nvidia,function = "clk";
				nvidia,pull = <0x00>;
				nvidia,tristate = <0x00>;
				nvidia,enable-input = <0x01>;
			};

			core_pwr_req {
				nvidia,pins = "core_pwr_req";
				nvidia,function = "pwron";
				nvidia,pull = <0x00>;
				nvidia,tristate = <0x00>;
				nvidia,enable-input = <0x00>;
			};

			cpu_pwr_req {
				nvidia,pins = "cpu_pwr_req";
				nvidia,function = "cpu";
				nvidia,pull = <0x00>;
				nvidia,tristate = <0x00>;
				nvidia,enable-input = <0x00>;
			};

			pwr_int_n {
				nvidia,pins = "pwr_int_n";
				nvidia,function = "pmi";
				nvidia,pull = <0x02>;
				nvidia,tristate = <0x00>;
				nvidia,enable-input = <0x01>;
			};

			reset_out_n {
				nvidia,pins = "reset_out_n";
				nvidia,function = "reset_out_n";
				nvidia,pull = <0x00>;
				nvidia,tristate = <0x00>;
				nvidia,enable-input = <0x00>;
			};

			pk0 {
				nvidia,pins = "pk0", "gpio_x1_aud_px1", "gpio_x4_aud_px4", "gpio_x5_aud_px5", "kb_row11_ps3", "sdmmc1_wp_n_pv3", "ulpi_data7_po0", "kb_col3_pq3", "gpio_x3_aud_px3";
				nvidia,pull = <0x00>;
				nvidia,tristate = <0x00>;
				nvidia,enable-input = <0x00>;
			};

			kb_row12_ps4 {
				nvidia,pins = "kb_row12_ps4";
				nvidia,pull = <0x01>;
				nvidia,tristate = <0x00>;
				nvidia,enable-input = <0x00>;
			};

			pb1 {
				nvidia,pins = "pb1", "kb_row9_ps1";
				nvidia,pull = <0x00>;
				nvidia,tristate = <0x00>;
				nvidia,enable-input = <0x00>;
			};

			kb_row7_pr7 {
				nvidia,pins = "kb_row7_pr7";
				nvidia,pull = <0x01>;
				nvidia,tristate = <0x00>;
				nvidia,enable-input = <0x01>;
			};

			kb_col0_pq0 {
				nvidia,pins = "kb_col0_pq0", "sdmmc3_cd_n_pv2", "kb_col5_pq5";
				nvidia,pull = <0x02>;
				nvidia,tristate = <0x00>;
				nvidia,enable-input = <0x01>;
			};

			pi3 {
				nvidia,pins = "pi3";
				nvidia,pull = <0x00>;
				nvidia,tristate = <0x00>;
				nvidia,enable-input = <0x00>;
			};

			gpio_w3_aud_pw3 {
				nvidia,pins = "gpio_w3_aud_pw3", "kb_row10_ps2";
				nvidia,pull = <0x00>;
				nvidia,tristate = <0x00>;
				nvidia,enable-input = <0x01>;
			};

			kb_row11_ps3 {
				nvidia,pins = "kb_row11_ps3", "kb_col4_pq4";
				nvidia,pull = <0x00>;
				nvidia,tristate = <0x00>;
				nvidia,enable-input = <0x00>;
			};

			ulpi_data0_po1 {
				nvidia,pins = "ulpi_data0_po1", "ulpi_data1_po2", "ulpi_data2_po3", "ulpi_data3_po4", "ulpi_data4_po5", "ulpi_data5_po6", "pbb5", "kb_col7_pq7", "kb_row8_ps0", "kb_row13_ps5", "kb_row14_ps6", "pcc2", "pv0", "pv1";
				nvidia,pull = <0x01>;
				nvidia,tristate = <0x00>;
				nvidia,enable-input = <0x01>;
			};

			gpio_x6_aud_px6 {
				nvidia,pins = "gpio_x6_aud_px6", "pj0", "pk3", "pi6", "clk2_req_pcc5", "pk2", "sdmmc3_cd_n_pv2";
				nvidia,pull = <0x02>;
				nvidia,tristate = <0x00>;
				nvidia,enable-input = <0x01>;
			};

			gpio_x7_aud_px7 {
				nvidia,pins = "gpio_x7_aud_px7", "pbb3", "pbb7", "ph2", "ph3", "ph6", "ph7", "pk1", "pi0", "kb_row1_pr1", "kb_row2_pr2", "kb_row5_pr5", "clk3_req_pee1", "pu2", "pu3", "pu4";
				nvidia,pull = <0x00>;
				nvidia,tristate = <0x00>;
				nvidia,enable-input = <0x00>;
			};

			gpio_w2_aud_pw2 {
				nvidia,pins = "gpio_w2_aud_pw2", "pi5", "pc7", "kb_col1_pq1", "kb_row4_pr4", "pu6", "spdif_out_pk5";
				nvidia,pull = <0x00>;
				nvidia,tristate = <0x00>;
				nvidia,enable-input = <0x01>;
			};

			pcc1 {
				nvidia,pins = "pcc1", "pcc2", "usb_vbus_en0_pn4", "pu5";
				nvidia,pull = <0x01>;
				nvidia,tristate = <0x00>;
				nvidia,enable-input = <0x01>;
			};

			kb_col2_pq2 {
				nvidia,pins = "kb_col2_pq2", "kb_row0_pr0";
				nvidia,pull = <0x02>;
				nvidia,tristate = <0x00>;
				nvidia,enable-input = <0x00>;
			};

			dap_mclk1_req_pee2 {
				nvidia,pins = "dap_mclk1_req_pee2", "pex_l0_clkreq_n_pdd2", "pex_l0_rst_n_pdd1", "pex_l1_clkreq_n_pdd6", "pex_l1_rst_n_pdd5", "pex_wake_n_pdd3", "pff2", "kb_row15_ps7", "kb_row16_pt0", "kb_row17_pt1", "owr";
				nvidia,pull = <0x01>;
				nvidia,tristate = <0x01>;
				nvidia,enable-input = <0x00>;
			};
		};
	};

	serial@70006000 {
		compatible = "nvidia,tegra124-uart", "nvidia,tegra20-uart";
		reg = <0x00 0x70006000 0x00 0x40>;
		reg-shift = <0x02>;
		interrupts = <0x00 0x24 0x04>;
		clocks = <0x03 0x06>;
		clock-names = "serial";
		resets = <0x03 0x06>;
		reset-names = "serial";
		dmas = <0x11 0x08 0x11 0x08>;
		dma-names = "rx", "tx";
		status = "okay";
	};

	serial@70006040 {
		compatible = "nvidia,tegra124-uart", "nvidia,tegra20-uart";
		reg = <0x00 0x70006040 0x00 0x40>;
		reg-shift = <0x02>;
		interrupts = <0x00 0x25 0x04>;
		clocks = <0x03 0xc0>;
		clock-names = "serial";
		resets = <0x03 0x07>;
		reset-names = "serial";
		dmas = <0x11 0x09 0x11 0x09>;
		dma-names = "rx", "tx";
		status = "disabled";
	};

	serial@70006200 {
		compatible = "nvidia,tegra124-uart", "nvidia,tegra20-uart";
		reg = <0x00 0x70006200 0x00 0x40>;
		reg-shift = <0x02>;
		interrupts = <0x00 0x2e 0x04>;
		clocks = <0x03 0x37>;
		clock-names = "serial";
		resets = <0x03 0x37>;
		reset-names = "serial";
		dmas = <0x11 0x0a 0x11 0x0a>;
		dma-names = "rx", "tx";
		status = "disabled";
	};

	serial@70006300 {
		compatible = "nvidia,tegra124-uart", "nvidia,tegra20-uart";
		reg = <0x00 0x70006300 0x00 0x40>;
		reg-shift = <0x02>;
		interrupts = <0x00 0x5a 0x04>;
		clocks = <0x03 0x41>;
		clock-names = "serial";
		resets = <0x03 0x41>;
		reset-names = "serial";
		dmas = <0x11 0x13 0x11 0x13>;
		dma-names = "rx", "tx";
		status = "disabled";
	};

	pwm@7000a000 {
		compatible = "nvidia,tegra124-pwm", "nvidia,tegra20-pwm";
		reg = <0x00 0x7000a000 0x00 0x100>;
		#pwm-cells = <0x02>;
		clocks = <0x03 0x11>;
		clock-names = "pwm";
		resets = <0x03 0x11>;
		reset-names = "pwm";
		status = "disabled";
	};

	i2c@7000c000 {
		compatible = "nvidia,tegra124-i2c";
		reg = <0x00 0x7000c000 0x00 0x100>;
		interrupts = <0x00 0x26 0x04>;
		#address-cells = <0x01>;
		#size-cells = <0x00>;
		clocks = <0x03 0x0c>;
		clock-names = "div-clk";
		resets = <0x03 0x0c>;
		reset-names = "i2c";
		dmas = <0x11 0x15 0x11 0x15>;
		dma-names = "rx", "tx";
		status = "okay";
		clock-frequency = <0x61a80>;

		max17050@36 {
			compatible = "maxim,max17050";
			reg = <0x36>;
			maxim,cold-temp = <0xffffffff>;
			maxim,over-heat-temp = <0x227>;
			maxim,over-volt = <0x1100>;
			phandle = <0x13>;
		};

		cm32181@48 {
			compatible = "capella,cm3218";
			status = "disabled";
			reg = <0x48>;
		};

		nct72@4c {
			compatible = "onnn,nct1008";
			reg = <0x4c>;
			vcc-supply = <0x12>;
			#thermal-sensor-cells = <0x01>;
		};

		bq24193@6b {
			compatible = "ti,bq24192";
			reg = <0x6b>;
			interrupt-parent = <0x0a>;
			interrupts = <0x48 0x00>;
			monitored-battery = <0x13>;
			omit-battery-class;

			usb-otg-vbus {
				phandle = <0x1f>;
			};
		};

		htc_mcu@72 {
			compatible = "htc,sensorhub";
			status = "disabled";
			reg = <0x72>;
		};

		bcm20791@77 {
			compatible = "broadcom,bcm20791";
			status = "disabled";
			reg = <0x77>;
		};
	};

	i2c@7000c400 {
		compatible = "nvidia,tegra124-i2c";
		reg = <0x00 0x7000c400 0x00 0x100>;
		interrupts = <0x00 0x54 0x04>;
		#address-cells = <0x01>;
		#size-cells = <0x00>;
		clocks = <0x03 0x36>;
		clock-names = "div-clk";
		resets = <0x03 0x36>;
		reset-names = "i2c";
		dmas = <0x11 0x16 0x11 0x16>;
		dma-names = "rx", "tx";
		status = "okay";
		clock-frequency = <0x61a80>;

		rt5677@2d {
			compatible = "realtek,rt5677";
			status = "disabled";
			reg = <0x2d>;
		};

		tfa9895@34 {
			compatible = "nxp,tfa9895";
			status = "disabled";
			reg = <0x34>;
		};

		tfa9895l@35 {
			compatible = "nxp,tfa9895";
			status = "disabled";
			reg = <0x35>;
		};

		ina230@40 {
			compatible = "ti,ina230";
			reg = <0x40>;
			shunt-resistor = <0x2710>;
		};

		rt5506@52 {
			compatible = "realtek,rt5506";
			status = "disabled";
			reg = <0x52>;
		};
	};

	i2c@7000c500 {
		compatible = "nvidia,tegra124-i2c";
		reg = <0x00 0x7000c500 0x00 0x100>;
		interrupts = <0x00 0x5c 0x04>;
		#address-cells = <0x01>;
		#size-cells = <0x00>;
		clocks = <0x03 0x43>;
		clock-names = "div-clk";
		resets = <0x03 0x43>;
		reset-names = "i2c";
		dmas = <0x11 0x17 0x11 0x17>;
		dma-names = "rx", "tx";
		status = "okay";
		clock-frequency = <0x61a80>;

		drv201@e {
			compatible = "ti,drv201";
			status = "disabled";
			reg = <0x0e>;
		};

		imx219@10 {
			compatible = "sony,imx219";
			status = "disabled";
			reg = <0x10>;
		};

		ov9760@36 {
			compatible = "omnivision,ov9760";
			status = "disabled";
			reg = <0x36>;
		};
	};

	i2c@7000c700 {
		compatible = "nvidia,tegra124-i2c";
		reg = <0x00 0x7000c700 0x00 0x100>;
		interrupts = <0x00 0x78 0x04>;
		#address-cells = <0x01>;
		#size-cells = <0x00>;
		clocks = <0x03 0x67>;
		clock-names = "div-clk";
		resets = <0x03 0x67>;
		reset-names = "i2c";
		dmas = <0x11 0x1a 0x11 0x1a>;
		dma-names = "rx", "tx";
		status = "disabled";
	};

	i2c@7000d000 {
		compatible = "nvidia,tegra124-i2c";
		reg = <0x00 0x7000d000 0x00 0x100>;
		interrupts = <0x00 0x35 0x04>;
		#address-cells = <0x01>;
		#size-cells = <0x00>;
		clocks = <0x03 0x2f>;
		clock-names = "div-clk";
		resets = <0x03 0x2f>;
		reset-names = "i2c";
		dmas = <0x11 0x18 0x11 0x18>;
		dma-names = "rx", "tx";
		status = "okay";
		clock-frequency = <0x61a80>;

		tps65913@58 {
			compatible = "ti,tps65913", "ti,palmas";
			reg = <0x58>;
			interrupts = <0x00 0x56 0x00>;
			#interrupt-cells = <0x02>;
			interrupt-controller;
			ti,system-power-controller;
			phandle = <0x14>;

			gpio {
				compatible = "ti,tps65913-gpio";
				gpio-controller;
				#gpio-cells = <0x02>;
			};

			rtc {
				compatible = "ti,palmas-rtc";
				interrupt-parent = <0x14>;
				interrupts = <0x08 0x00>;
			};

			pinctrl {
				compatible = "ti,tps65913-pinctrl";
				pinctrl-names = "default";
				pinctrl-0 = <0x15>;

				pinmux {
					phandle = <0x15>;

					powergood {
						pins = "powergood";
						function = "powergood";
					};

					vac {
						pins = "vac";
						function = "vac";
					};

					pin_gpio0 {
						pins = "gpio0";
						function = "id";
						bias-pull-up;
					};

					pin_gpio1 {
						pins = "gpio1";
						function = "vbus_det";
					};

					pin_gpio7 {
						pins = "gpio2", "gpio3", "gpio4", "gpio6", "gpio7";
						function = "gpio";
					};

					pin_gpio5 {
						pins = "gpio5";
						function = "clk32kgaudio";
					};
				};
			};

			palmas-usb {
				compatible = "ti,palmas-usb-vid";
				ti,wakeup;
				ti,enable-vbus-detection;
				phandle = <0x26>;
			};

			clock {
				compatible = "ti,palmas-clk32kg";
				#clock-cells = <0x00>;
			};

			pmic {
				compatible = "ti,tps65913-pmic", "ti,palmas-pmic";
				smps1-in-supply = <0x16>;
				smps4-in-supply = <0x16>;
				smps6-in-supply = <0x16>;
				smps8-in-supply = <0x16>;
				smps9-in-supply = <0x16>;
				smps10-in-supply = <0x16>;
				smps10-out2-supply = <0x16>;
				ldo1-in-supply = <0x16>;
				ldo2-in-supply = <0x17>;
				ldo3-in-supply = <0x16>;
				ldo4-in-supply = <0x16>;
				ldo5-in-supply = <0x17>;
				ldo6-in-supply = <0x16>;
				ldo7-in-supply = <0x17>;
				ldo8-in-supply = <0x16>;
				ldo9-in-supply = <0x16>;
				ldoln-in-supply = <0x18>;
				ldousb-in-supply = <0x16>;

				regulators {

					smps123 {
						regulator-name = "vdd-cpu";
						regulator-min-microvolt = <0x9eb10>;
						regulator-max-microvolt = <0x155cc0>;
						regulator-always-on;
						regulator-boot-on;
						ti,roof-floor = <0x01>;
						phandle = <0x1b>;
					};

					smps457 {
						regulator-name = "vdd-gpu";
						regulator-min-microvolt = <0xaae60>;
						regulator-max-microvolt = <0x155cc0>;
						phandle = <0x0d>;
					};

					smps6 {
						regulator-name = "vdd-core";
						regulator-min-microvolt = <0xaae60>;
						regulator-max-microvolt = <0x155cc0>;
						regulator-always-on;
						regulator-boot-on;
						ti,roof-floor = <0x03>;
					};

					smps8 {
						regulator-name = "vdd-1v8";
						regulator-min-microvolt = <0x1b7740>;
						regulator-max-microvolt = <0x1b7740>;
						regulator-always-on;
						regulator-boot-on;
						phandle = <0x17>;
					};

					smps9 {
						regulator-name = "vdd-1v2";
						regulator-min-microvolt = <0x124f80>;
						regulator-max-microvolt = <0x124f80>;
					};

					smps10_out1 {
						regulator-name = "vdd-hdmi";
						regulator-min-microvolt = <0x4c4b40>;
						regulator-max-microvolt = <0x4c4b40>;
					};

					smps10_out2 {
						regulator-name = "vdd-out2-5v0";
						regulator-min-microvolt = <0x4c4b40>;
						regulator-max-microvolt = <0x4c4b40>;
						regulator-always-on;
						regulator-boot-on;
						phandle = <0x18>;
					};

					ldo1 {
						regulator-name = "avdd-pll";
						regulator-min-microvolt = <0x100590>;
						regulator-max-microvolt = <0x100590>;
						regulator-always-on;
						regulator-boot-on;
						ti,roof-floor = <0x03>;
						phandle = <0x1d>;
					};

					ldo2 {
						regulator-name = "vdd-audio";
						regulator-min-microvolt = <0x124f80>;
						regulator-max-microvolt = <0x124f80>;
					};

					ldo3 {
						regulator-name = "vdd-sensor-io";
						regulator-min-microvolt = <0x1b7740>;
						regulator-max-microvolt = <0x1b7740>;
					};

					ldo4 {
						regulator-name = "vdd-sensor-2v85";
						regulator-min-microvolt = <0x2b7cd0>;
						regulator-max-microvolt = <0x2b7cd0>;
						regulator-always-on;
						phandle = <0x12>;
					};

					ldo5 {
						regulator-name = "avdd-dsi-csi";
						regulator-min-microvolt = <0x124f80>;
						regulator-max-microvolt = <0x124f80>;
						regulator-boot-on;
						phandle = <0x06>;
					};

					ldo6 {
						regulator-name = "vdd-1v5-ldo6";
						regulator-min-microvolt = <0x16e360>;
						regulator-max-microvolt = <0x1b7740>;
					};

					ldo7 {
						regulator-name = "dvdd-slimport";
						regulator-min-microvolt = <0xf4240>;
						regulator-max-microvolt = <0x10c8e0>;
					};

					ldo8 {
						regulator-name = "vdd-rtc";
						regulator-min-microvolt = <0xe7ef0>;
						regulator-max-microvolt = <0xe7ef0>;
						regulator-always-on;
						regulator-boot-on;
					};

					ldo9 {
						regulator-name = "vdd-3p3-ldo9";
						regulator-min-microvolt = <0x1b7740>;
						regulator-max-microvolt = <0x325aa0>;
					};

					ldoln {
						regulator-name = "vddio-hv";
						regulator-min-microvolt = <0x325aa0>;
						regulator-max-microvolt = <0x325aa0>;
						ti,roof-floor = <0x03>;
					};

					ldousb {
						regulator-name = "avdd-usb";
						regulator-min-microvolt = <0x325aa0>;
						regulator-max-microvolt = <0x325aa0>;
						phandle = <0x1e>;
					};
				};
			};

			adc {
				compatible = "ti,palmas-gpadc";
				interrupts = <0x12 0x00 0x10 0x00 0x11 0x00>;
				#io-channel-cells = <0x01>;
			};
		};
	};

	i2c@7000d100 {
		compatible = "nvidia,tegra124-i2c";
		reg = <0x00 0x7000d100 0x00 0x100>;
		interrupts = <0x00 0x3f 0x04>;
		#address-cells = <0x01>;
		#size-cells = <0x00>;
		clocks = <0x03 0xa6>;
		clock-names = "div-clk";
		resets = <0x03 0xa6>;
		reset-names = "i2c";
		dmas = <0x11 0x1e 0x11 0x1e>;
		dma-names = "rx", "tx";
		status = "disabled";
	};

	spi@7000d400 {
		compatible = "nvidia,tegra124-spi", "nvidia,tegra114-spi";
		reg = <0x00 0x7000d400 0x00 0x200>;
		interrupts = <0x00 0x3b 0x04>;
		#address-cells = <0x01>;
		#size-cells = <0x00>;
		clocks = <0x03 0x29>;
		clock-names = "spi";
		resets = <0x03 0x29>;
		reset-names = "spi";
		dmas = <0x11 0x0f 0x11 0x0f>;
		dma-names = "rx", "tx";
		status = "disabled";
	};

	spi@7000d600 {
		compatible = "nvidia,tegra124-spi", "nvidia,tegra114-spi";
		reg = <0x00 0x7000d600 0x00 0x200>;
		interrupts = <0x00 0x52 0x04>;
		#address-cells = <0x01>;
		#size-cells = <0x00>;
		clocks = <0x03 0x2c>;
		clock-names = "spi";
		resets = <0x03 0x2c>;
		reset-names = "spi";
		dmas = <0x11 0x10 0x11 0x10>;
		dma-names = "rx", "tx";
		status = "disabled";
	};

	spi@7000d800 {
		compatible = "nvidia,tegra124-spi", "nvidia,tegra114-spi";
		reg = <0x00 0x7000d800 0x00 0x200>;
		interrupts = <0x00 0x53 0x04>;
		#address-cells = <0x01>;
		#size-cells = <0x00>;
		clocks = <0x03 0x2e>;
		clock-names = "spi";
		resets = <0x03 0x2e>;
		reset-names = "spi";
		dmas = <0x11 0x11 0x11 0x11>;
		dma-names = "rx", "tx";
		status = "okay";
		spi-max-frequency = <0x17d7840>;

		touchscreen@0 {
			compatible = "syna,rmi4-spi";
			reg = <0x00>;
			#address-cells = <0x01>;
			#size-cells = <0x00>;
			spi-max-frequency = "", "=\t";
			spi-cpha;
			spi-cpol;
			interrupt-parent = <0x0a>;
			interrupts = <0x52 0x02>;
			spi-rx-delay-us = <0x1e>;
			spi-tx-delay-us = <0x1e>;

			rmi-f01@1 {
				reg = <0x01>;
				syna,nosleep = <0x01>;
			};

			rmi-f12@12 {
				reg = <0x12>;
				syna,sensor-type = <0x01>;
			};
		};
	};

	spi@7000da00 {
		compatible = "nvidia,tegra124-spi", "nvidia,tegra114-spi";
		reg = <0x00 0x7000da00 0x00 0x200>;
		interrupts = <0x00 0x5d 0x04>;
		#address-cells = <0x01>;
		#size-cells = <0x00>;
		clocks = <0x03 0x44>;
		clock-names = "spi";
		resets = <0x03 0x44>;
		reset-names = "spi";
		dmas = <0x11 0x12 0x11 0x12>;
		dma-names = "rx", "tx";
		status = "okay";
		spi-max-frequency = <0x17d7840>;
	};

	spi@7000dc00 {
		compatible = "nvidia,tegra124-spi", "nvidia,tegra114-spi";
		reg = <0x00 0x7000dc00 0x00 0x200>;
		interrupts = <0x00 0x5e 0x04>;
		#address-cells = <0x01>;
		#size-cells = <0x00>;
		clocks = <0x03 0x68>;
		clock-names = "spi";
		resets = <0x03 0x68>;
		reset-names = "spi";
		dmas = <0x11 0x1b 0x11 0x1b>;
		dma-names = "rx", "tx";
		status = "okay";
		spi-max-frequency = <0x17d7840>;

		rt5677@0 {
			compatible = "realtek,rt5677";
			status = "disabled";
			reg = <0x00>;
		};
	};

	spi@7000de00 {
		compatible = "nvidia,tegra124-spi", "nvidia,tegra114-spi";
		reg = <0x00 0x7000de00 0x00 0x200>;
		interrupts = <0x00 0x4f 0x04>;
		#address-cells = <0x01>;
		#size-cells = <0x00>;
		clocks = <0x03 0x69>;
		clock-names = "spi";
		resets = <0x03 0x69>;
		reset-names = "spi";
		dmas = <0x11 0x1c 0x11 0x1c>;
		dma-names = "rx", "tx";
		status = "disabled";
	};

	rtc@7000e000 {
		compatible = "nvidia,tegra124-rtc", "nvidia,tegra20-rtc";
		reg = <0x00 0x7000e000 0x00 0x100>;
		interrupts = <0x00 0x02 0x04>;
		clocks = <0x03 0x04>;
		clock-names = "rtc";
	};

	pmc@7000e400 {
		compatible = "nvidia,tegra124-pmc";
		reg = <0x00 0x7000e400 0x00 0x400>;
		clocks = <0x03 0x105 0x19>;
		clock-names = "pclk", "clk32k_in";
		#clock-cells = <0x01>;
		nvidia,invert-interrupt;
		nvidia,suspend-mode = <0x00>;
		nvidia,cpu-pwr-good-time = <0x1f4>;
		nvidia,cpu-pwr-off-time = <0x12c>;
		nvidia,core-pwr-good-time = <0x281 0xf05>;
		nvidia,core-pwr-off-time = <0x7d0>;
		nvidia,core-power-req-active-high;
		nvidia,sys-clock-req-active-high;
		phandle = <0x28>;

		i2c-thermtrip {
			nvidia,i2c-controller-id = <0x04>;
			nvidia,bus-addr = <0x58>;
			nvidia,reg-addr = <0xa0>;
			nvidia,reg-data = <0x00>;
		};
	};

	fuse@7000f800 {
		compatible = "nvidia,tegra132-efuse";
		reg = <0x00 0x7000f800 0x00 0x400>;
		clocks = <0x03 0xc6>;
		clock-names = "fuse";
		resets = <0x03 0x27>;
		reset-names = "fuse";
	};

	memory-controller@70019000 {
		compatible = "nvidia,tegra132-mc";
		reg = <0x00 0x70019000 0x00 0x1000>;
		clocks = <0x03 0x20>;
		clock-names = "mc";
		interrupts = <0x00 0x4d 0x04>;
		#iommu-cells = <0x01>;
		#reset-cells = <0x01>;
		#interconnect-cells = <0x01>;
		phandle = <0x04>;

		emc-timings-1 {
			nvidia,ram-code = <0x01>;

			timing-12750000 {
				clock-frequency = <0xc28cb0>;
				nvidia,emem-configuration = <0x40040001 0x8000000a 0x01 0x01 0x02 0x00 0x03 0x01 0x02 0x07 0x02 0x01 0x04 0x05 0x5040102 0x90402 0x77c30303 0x70000f03 0x1f0000>;
			};

			timing-20400000 {
				clock-frequency = <0x1374780>;
				nvidia,emem-configuration = <0x40020001 0x80000012 0x01 0x01 0x02 0x00 0x03 0x01 0x02 0x07 0x02 0x01 0x04 0x05 0x5040102 0x90402 0x74e30303 0x70000f03 0x1f0000>;
			};

			timing-40800000 {
				clock-frequency = <0x26e8f00>;
				nvidia,emem-configuration = <0xa0000001 0x80000017 0x01 0x01 0x02 0x00 0x03 0x01 0x02 0x07 0x02 0x01 0x04 0x05 0x5040102 0x90402 0x73030303 0x70000f03 0x1f0000>;
			};

			timing-68000000 {
				clock-frequency = <0x40d9900>;
				nvidia,emem-configuration = <0x01 0x8000001e 0x01 0x01 0x02 0x00 0x03 0x01 0x02 0x07 0x02 0x01 0x04 0x05 0x5040102 0x90402 0x72630403 0x70000f03 0x1f0000>;
			};

			timing-102000000 {
				clock-frequency = <0x6146580>;
				nvidia,emem-configuration = <0x8000001 0x80000026 0x01 0x01 0x03 0x01 0x03 0x01 0x02 0x07 0x02 0x01 0x04 0x05 0x5040102 0x90403 0x72430504 0x70000f03 0x1f0000>;
			};

			timing-136000000 {
				clock-frequency = <0x81b3200>;
				nvidia,emem-configuration = <0x1000002 0x8000002f 0x01 0x01 0x04 0x01 0x03 0x01 0x02 0x07 0x02 0x01 0x05 0x05 0x5050102 0x90404 0x72030705 0x70000f03 0x1f0000>;
			};

			timing-204000000 {
				clock-frequency = <0xc28cb00>;
				nvidia,emem-configuration = <0x1000003 0x80000040 0x01 0x01 0x06 0x03 0x05 0x01 0x02 0x07 0x03 0x01 0x05 0x05 0x5050103 0xa0506 0x71e40a07 0x70000f03 0x1f0000>;
			};

			timing-300000000 {
				clock-frequency = <0x11e1a300>;
				nvidia,emem-configuration = <0x8000004 0x80000040 0x01 0x02 0x09 0x05 0x07 0x01 0x02 0x07 0x03 0x01 0x05 0x05 0x5050103 0xc0709 0x71c50e0a 0x70000f03 0x1f0000>;
			};

			timing-396000000 {
				clock-frequency = <0x179a7b00>;
				nvidia,emem-configuration = <0xf000005 0x80000040 0x02 0x03 0x0c 0x07 0x09 0x01 0x02 0x07 0x03 0x01 0x05 0x05 0x5050103 0xe090c 0x71c6120d 0x70000f03 0x1f0000>;
			};

			timing-528000000 {
				clock-frequency = <0x1f78a400>;
				nvidia,emem-configuration = <0xf000007 0x80000040 0x03 0x04 0x10 0x0a 0x0d 0x02 0x02 0x09 0x03 0x01 0x06 0x06 0x6060103 0x120b10 0x71c81811 0x70000f03 0x1f0000>;
			};

			timing-600000000 {
				clock-frequency = <0x23c34600>;
				nvidia,emem-configuration = <0x09 0x80000040 0x04 0x05 0x12 0x0b 0x0e 0x02 0x03 0x0a 0x03 0x01 0x06 0x07 0x7060103 0x140d12 0x71a91b13 0x70000f03 0x1f0000>;
			};

			timing-792000000 {
				clock-frequency = <0x2f34f600>;
				nvidia,emem-configuration = <0xe00000b 0x80000040 0x06 0x07 0x18 0x0f 0x13 0x03 0x03 0x0c 0x03 0x01 0x08 0x08 0x8080103 0x1a1118 0x71ac2419 0x70000f02 0x1f0000>;
			};

			timing-924000000 {
				clock-frequency = <0x37131f00>;
				nvidia,emem-configuration = <0xe00000d 0x80000040 0x07 0x08 0x1b 0x12 0x17 0x04 0x04 0x0e 0x04 0x01 0x09 0x09 0x9090104 0x1e141b 0x71ae2a1c 0x70000f02 0x1f0000>;
			};
		};

		emc-timings-2 {
			nvidia,ram-code = <0x02>;

			timing-12750000 {
				clock-frequency = <0xc28cb0>;
				nvidia,emem-configuration = <0x40040001 0x8000000a 0x01 0x01 0x02 0x00 0x03 0x01 0x02 0x07 0x02 0x01 0x04 0x05 0x5040102 0x90402 0x77c30303 0x70000f03 0x1f0000>;
			};

			timing-20400000 {
				clock-frequency = <0x1374780>;
				nvidia,emem-configuration = <0x40020001 0x80000012 0x01 0x01 0x02 0x00 0x03 0x01 0x02 0x07 0x02 0x01 0x04 0x05 0x5040102 0x90402 0x74e30303 0x70000f03 0x1f0000>;
			};

			timing-40800000 {
				clock-frequency = <0x26e8f00>;
				nvidia,emem-configuration = <0xa0000001 0x80000017 0x01 0x01 0x02 0x00 0x03 0x01 0x02 0x07 0x02 0x01 0x04 0x05 0x5040102 0x90402 0x73030303 0x70000f03 0x1f0000>;
			};

			timing-68000000 {
				clock-frequency = <0x40d9900>;
				nvidia,emem-configuration = <0x01 0x8000001e 0x01 0x01 0x02 0x00 0x03 0x01 0x02 0x07 0x02 0x01 0x04 0x05 0x5040102 0x90402 0x72630403 0x70000f03 0x1f0000>;
			};

			timing-102000000 {
				clock-frequency = <0x6146580>;
				nvidia,emem-configuration = <0x8000001 0x80000026 0x01 0x01 0x03 0x01 0x03 0x01 0x02 0x07 0x02 0x01 0x04 0x05 0x5040102 0x90403 0x72430504 0x70000f03 0x1f0000>;
			};

			timing-136000000 {
				clock-frequency = <0x81b3200>;
				nvidia,emem-configuration = <0x1000002 0x8000002f 0x01 0x01 0x04 0x01 0x03 0x01 0x02 0x07 0x02 0x01 0x05 0x05 0x5050102 0x90404 0x72030705 0x70000f03 0x1f0000>;
			};

			timing-204000000 {
				clock-frequency = <0xc28cb00>;
				nvidia,emem-configuration = <0x1000003 0x80000040 0x01 0x01 0x06 0x03 0x05 0x01 0x02 0x07 0x03 0x01 0x05 0x05 0x5050103 0xa0506 0x71e40a07 0x70000f03 0x1f0000>;
			};

			timing-300000000 {
				clock-frequency = <0x11e1a300>;
				nvidia,emem-configuration = <0x8000004 0x80000040 0x01 0x02 0x09 0x05 0x07 0x01 0x02 0x07 0x03 0x01 0x05 0x05 0x5050103 0xc0709 0x71c50e0a 0x70000f03 0x1f0000>;
			};

			timing-396000000 {
				clock-frequency = <0x179a7b00>;
				nvidia,emem-configuration = <0xf000005 0x80000040 0x02 0x03 0x0c 0x07 0x09 0x01 0x02 0x07 0x03 0x01 0x05 0x05 0x5050103 0xe090c 0x71c6120d 0x70000f03 0x1f0000>;
			};

			timing-528000000 {
				clock-frequency = <0x1f78a400>;
				nvidia,emem-configuration = <0xf000007 0x80000040 0x03 0x04 0x10 0x0a 0x0d 0x02 0x02 0x09 0x03 0x01 0x06 0x06 0x6060103 0x120b10 0x71c81811 0x70000f03 0x1f0000>;
			};

			timing-600000000 {
				clock-frequency = <0x23c34600>;
				nvidia,emem-configuration = <0x09 0x80000040 0x04 0x05 0x12 0x0b 0x0e 0x02 0x03 0x0a 0x03 0x01 0x06 0x07 0x7060103 0x140d12 0x71a91b13 0x70000f03 0x1f0000>;
			};

			timing-792000000 {
				clock-frequency = <0x2f34f600>;
				nvidia,emem-configuration = <0xe00000b 0x80000040 0x06 0x07 0x18 0x0f 0x13 0x03 0x03 0x0c 0x03 0x01 0x08 0x08 0x8080103 0x1a1118 0x71ac2419 0x70000f02 0x1f0000>;
			};

			timing-924000000 {
				clock-frequency = <0x37131f00>;
				nvidia,emem-configuration = <0xe00000d 0x80000040 0x07 0x08 0x1b 0x12 0x17 0x04 0x04 0x0e 0x04 0x01 0x09 0x09 0x9090104 0x1e141b 0x71ae2a1c 0x70000f02 0x1f0000>;
			};
		};
	};

	external-memory-controller@7001b000 {
		compatible = "nvidia,tegra132-emc", "nvidia,tegra124-emc";
		reg = <0x00 0x7001b000 0x00 0x1000>;
		clocks = <0x03 0x39>;
		clock-names = "emc";
		nvidia,memory-controller = <0x04>;
		operating-points-v2 = <0x1a>;
		#interconnect-cells = <0x00>;
		phandle = <0x0e>;

		emc-timings-1 {
			nvidia,ram-code = <0x01>;

			timing-12750000 {
				clock-frequency = <0xc28cb0>;
				nvidia,emc-auto-cal-config = <0xa1430000>;
				nvidia,emc-auto-cal-config2 = <0x00>;
				nvidia,emc-auto-cal-config3 = <0x00>;
				nvidia,emc-auto-cal-interval = <0x1fffff>;
				nvidia,emc-bgbias-ctl0 = <0x08>;
				nvidia,emc-cfg = <0xf3200000>;
				nvidia,emc-cfg-2 = <0x8c7>;
				nvidia,emc-ctt-term-ctrl = <0x802>;
				nvidia,emc-mode-1 = <0x10083>;
				nvidia,emc-mode-2 = <0x20004>;
				nvidia,emc-mode-4 = <0x800b0000>;
				nvidia,emc-mode-reset = <0x00>;
				nvidia,emc-mrs-wait-cnt = <0xd0011>;
				nvidia,emc-sel-dpd-ctrl = <0x4013c>;
				nvidia,emc-xm2dqspadctrl2 = <0x130b018>;
				nvidia,emc-zcal-cnt-long = <0x15>;
				nvidia,emc-zcal-interval = <0x64000>;
				nvidia,emc-configuration = <0x00 0x03 0x00 0x02 0x02 0x06 0x08 0x03 0x0a 0x02 0x02 0x01 0x02 0x00 0x03 0x03 0x06 0x02 0x00 0x05 0x05 0x10000 0x03 0x00 0x00 0x00 0x00 0x04 0x0c 0x0d 0x0f 0x30 0x00 0x0c 0x02 0x02 0x02 0x00 0x01 0x0c 0x03 0x02 0x03 0x03 0x03 0x06 0x04 0x03 0x03 0x36 0x00 0x00 0x00 0x1361a296 0x5800a0 0x8000 0x48000 0x48000 0x48000 0x48000 0x48000 0x48000 0x48000 0x48000 0x48000 0x48000 0x48000 0x48000 0x48000 0x48000 0x48000 0x48000 0x00 0x00 0x00 0x00 0x00 0x00 0x00 0x00 0xfc000 0xfc000 0x00 0xfc000 0xfc000 0x00 0x00 0x00 0x00 0x00 0x00 0x00 0x00 0x00 0x00 0x00 0x00 0x00 0x00 0x00 0x00 0x00 0x00 0x00 0x00 0x00 0x00 0x00 0x00 0x00 0xfc000 0xfc000 0xfc000 0xfc000 0xfc00 0xfc00 0xfc00 0xfc00 0x200 0x00 0x100100 0x00 0x00 0x77ffc000 0x404 0x81f1f008 0x7070000 0x3f 0x15ddddd 0x51451400 0x514514 0x514514 0x51451400 0x3f 0x00 0x00 0x11 0xd0011 0x00 0x03 0xf3f3 0x80000164 0x0a>;
			};

			timing-20400000 {
				clock-frequency = <0x1374780>;
				nvidia,emc-auto-cal-config = <0xa1430000>;
				nvidia,emc-auto-cal-config2 = <0x00>;
				nvidia,emc-auto-cal-config3 = <0x00>;
				nvidia,emc-auto-cal-interval = <0x1fffff>;
				nvidia,emc-bgbias-ctl0 = <0x08>;
				nvidia,emc-cfg = <0xf3200000>;
				nvidia,emc-cfg-2 = <0x8c7>;
				nvidia,emc-ctt-term-ctrl = <0x802>;
				nvidia,emc-mode-1 = <0x10083>;
				nvidia,emc-mode-2 = <0x20004>;
				nvidia,emc-mode-4 = <0x800b0000>;
				nvidia,emc-mode-reset = <0x00>;
				nvidia,emc-mrs-wait-cnt = <0x150011>;
				nvidia,emc-sel-dpd-ctrl = <0x4013c>;
				nvidia,emc-xm2dqspadctrl2 = <0x130b018>;
				nvidia,emc-zcal-cnt-long = <0x15>;
				nvidia,emc-zcal-interval = <0x64000>;
				nvidia,emc-configuration = <0x01 0x03 0x00 0x02 0x02 0x06 0x08 0x03 0x0a 0x02 0x02 0x01 0x02 0x00 0x03 0x03 0x06 0x02 0x00 0x05 0x05 0x10000 0x03 0x00 0x00 0x00 0x00 0x04 0x0c 0x0d 0x0f 0x4d 0x00 0x13 0x02 0x02 0x02 0x00 0x01 0x0c 0x03 0x03 0x03 0x03 0x03 0x06 0x04 0x03 0x03 0x55 0x00 0x00 0x00 0x1361a296 0x5800a0 0x8000 0x48000 0x48000 0x48000 0x48000 0x48000 0x48000 0x48000 0x48000 0x48000 0x48000 0x48000 0x48000 0x48000 0x48000 0x48000 0x48000 0x00 0x00 0x00 0x00 0x00 0x00 0x00 0x00 0xfc000 0xfc000 0x00 0xfc000 0xfc000 0x00 0x00 0x00 0x00 0x00 0x00 0x00 0x00 0x00 0x00 0x00 0x00 0x00 0x00 0x00 0x00 0x00 0x00 0x00 0x00 0x00 0x00 0x00 0x00 0x00 0xfc000 0xfc000 0xfc000 0xfc000 0xfc00 0xfc00 0xfc00 0xfc00 0x200 0x00 0x100100 0x00 0x00 0x77ffc000 0x404 0x81f1f008 0x7070000 0x3f 0x15ddddd 0x51451400 0x514514 0x514514 0x51451400 0x3f 0x00 0x00 0x11 0x150011 0x00 0x03 0xf3f3 0x8000019f 0x0a>;
			};

			timing-40800000 {
				clock-frequency = <0x26e8f00>;
				nvidia,emc-auto-cal-config = <0xa1430000>;
				nvidia,emc-auto-cal-config2 = <0x00>;
				nvidia,emc-auto-cal-config3 = <0x00>;
				nvidia,emc-auto-cal-interval = <0x1fffff>;
				nvidia,emc-bgbias-ctl0 = <0x08>;
				nvidia,emc-cfg = <0xf3200000>;
				nvidia,emc-cfg-2 = <0x8c7>;
				nvidia,emc-ctt-term-ctrl = <0x802>;
				nvidia,emc-mode-1 = <0x10083>;
				nvidia,emc-mode-2 = <0x20004>;
				nvidia,emc-mode-4 = <0x800b0000>;
				nvidia,emc-mode-reset = <0x00>;
				nvidia,emc-mrs-wait-cnt = <0x290011>;
				nvidia,emc-sel-dpd-ctrl = <0x4013c>;
				nvidia,emc-xm2dqspadctrl2 = <0x130b018>;
				nvidia,emc-zcal-cnt-long = <0x15>;
				nvidia,emc-zcal-interval = <0x64000>;
				nvidia,emc-configuration = <0x02 0x05 0x00 0x02 0x02 0x06 0x08 0x03 0x0a 0x02 0x02 0x01 0x02 0x00 0x03 0x03 0x06 0x02 0x00 0x05 0x05 0x10000 0x03 0x00 0x00 0x00 0x00 0x04 0x0c 0x0d 0x0f 0x9a 0x00 0x26 0x02 0x02 0x02 0x00 0x01 0x0c 0x06 0x06 0x03 0x03 0x03 0x06 0x04 0x03 0x03 0xaa 0x00 0x00 0x00 0x1361a296 0x5800a0 0x8000 0x48000 0x48000 0x48000 0x48000 0x48000 0x48000 0x48000 0x48000 0x48000 0x48000 0x48000 0x48000 0x48000 0x48000 0x48000 0x48000 0x00 0x00 0x00 0x00 0x00 0x00 0x00 0x00 0xfc000 0xfc000 0x00 0xfc000 0xfc000 0x00 0x00 0x00 0x00 0x00 0x00 0x00 0x00 0x00 0x00 0x00 0x00 0x00 0x00 0x00 0x00 0x00 0x00 0x00 0x00 0x00 0x00 0x00 0x00 0x00 0xfc000 0xfc000 0xfc000 0xfc000 0xfc00 0xfc00 0xfc00 0xfc00 0x200 0x00 0x100100 0x00 0x00 0x77ffc000 0x404 0x81f1f008 0x7070000 0x3f 0x15ddddd 0x51451400 0x514514 0x514514 0x51451400 0x3f 0x00 0x00 0x11 0x290011 0x00 0x03 0xf3f3 0x8000023a 0x0a>;
			};

			timing-68000000 {
				clock-frequency = <0x40d9900>;
				nvidia,emc-auto-cal-config = <0xa1430000>;
				nvidia,emc-auto-cal-config2 = <0x00>;
				nvidia,emc-auto-cal-config3 = <0x00>;
				nvidia,emc-auto-cal-interval = <0x1fffff>;
				nvidia,emc-bgbias-ctl0 = <0x08>;
				nvidia,emc-cfg = <0xf3200000>;
				nvidia,emc-cfg-2 = <0x8c7>;
				nvidia,emc-ctt-term-ctrl = <0x802>;
				nvidia,emc-mode-1 = <0x10083>;
				nvidia,emc-mode-2 = <0x20004>;
				nvidia,emc-mode-4 = <0x800b0000>;
				nvidia,emc-mode-reset = <0x00>;
				nvidia,emc-mrs-wait-cnt = <0x440011>;
				nvidia,emc-sel-dpd-ctrl = <0x4013c>;
				nvidia,emc-xm2dqspadctrl2 = <0x130b018>;
				nvidia,emc-zcal-cnt-long = <0x15>;
				nvidia,emc-zcal-interval = <0x64000>;
				nvidia,emc-configuration = <0x04 0x08 0x00 0x02 0x02 0x06 0x08 0x03 0x0a 0x02 0x02 0x01 0x02 0x00 0x03 0x03 0x06 0x02 0x00 0x05 0x05 0x10000 0x03 0x00 0x00 0x00 0x00 0x04 0x0c 0x0d 0x0f 0x101 0x00 0x40 0x02 0x02 0x02 0x00 0x01 0x0c 0x0a 0x0a 0x03 0x03 0x03 0x06 0x04 0x03 0x03 0x11b 0x00 0x00 0x00 0x1361a296 0x5800a0 0x8000 0x48000 0x48000 0x48000 0x48000 0x48000 0x48000 0x48000 0x48000 0x48000 0x48000 0x48000 0x48000 0x48000 0x48000 0x48000 0x48000 0x00 0x00 0x00 0x00 0x00 0x00 0x00 0x00 0xfc000 0xfc000 0x00 0xfc000 0xfc000 0x00 0x00 0x00 0x00 0x00 0x00 0x00 0x00 0x00 0x00 0x00 0x00 0x00 0x00 0x00 0x00 0x00 0x00 0x00 0x00 0x00 0x00 0x00 0x00 0x00 0xfc000 0xfc000 0xfc000 0xfc000 0xfc00 0xfc00 0xfc00 0xfc00 0x200 0x00 0x100100 0x00 0x00 0x77ffc000 0x404 0x81f1f008 0x7070000 0x3f 0x15ddddd 0x51451400 0x514514 0x514514 0x51451400 0x3f 0x00 0x00 0x19 0x440011 0x00 0x03 0xf3f3 0x80000309 0x0a>;
			};

			timing-102000000 {
				clock-frequency = <0x6146580>;
				nvidia,emc-auto-cal-config = <0xa1430000>;
				nvidia,emc-auto-cal-config2 = <0x00>;
				nvidia,emc-auto-cal-config3 = <0x00>;
				nvidia,emc-auto-cal-interval = <0x1fffff>;
				nvidia,emc-bgbias-ctl0 = <0x08>;
				nvidia,emc-cfg = <0xf3200000>;
				nvidia,emc-cfg-2 = <0x8c7>;
				nvidia,emc-ctt-term-ctrl = <0x802>;
				nvidia,emc-mode-1 = <0x10083>;
				nvidia,emc-mode-2 = <0x20004>;
				nvidia,emc-mode-4 = <0x800b0000>;
				nvidia,emc-mode-reset = <0x00>;
				nvidia,emc-mrs-wait-cnt = <0x660011>;
				nvidia,emc-sel-dpd-ctrl = <0x4013c>;
				nvidia,emc-xm2dqspadctrl2 = <0x130b018>;
				nvidia,emc-zcal-cnt-long = <0x15>;
				nvidia,emc-zcal-interval = <0x64000>;
				nvidia,emc-configuration = <0x06 0x0d 0x00 0x04 0x02 0x06 0x08 0x03 0x0a 0x02 0x02 0x01 0x02 0x00 0x03 0x03 0x06 0x02 0x00 0x05 0x05 0x10000 0x03 0x00 0x00 0x00 0x00 0x04 0x0c 0x0d 0x0f 0x182 0x00 0x60 0x02 0x02 0x02 0x00 0x01 0x0c 0x0f 0x0f 0x03 0x03 0x03 0x06 0x04 0x03 0x03 0x1a9 0x00 0x00 0x00 0x1361a296 0x5800a0 0x8000 0x48000 0x48000 0x48000 0x48000 0x48000 0x48000 0x48000 0x48000 0x48000 0x48000 0x48000 0x48000 0x48000 0x48000 0x48000 0x48000 0x00 0x00 0x00 0x00 0x00 0x00 0x00 0x00 0xfc000 0xfc000 0x00 0xfc000 0xfc000 0x00 0x00 0x00 0x00 0x00 0x00 0x00 0x00 0x00 0x00 0x00 0x00 0x00 0x00 0x00 0x00 0x00 0x00 0x00 0x00 0x00 0x00 0x00 0x00 0x00 0xfc000 0xfc000 0xfc000 0xfc000 0xfc00 0xfc00 0xfc00 0xfc00 0x200 0x00 0x100100 0x00 0x00 0x77ffc000 0x404 0x81f1f008 0x7070000 0x3f 0x15ddddd 0x51451400 0x514514 0x514514 0x51451400 0x3f 0x00 0x00 0x25 0x660011 0x00 0x03 0xf3f3 0x8000040b 0x0a>;
			};

			timing-136000000 {
				clock-frequency = <0x81b3200>;
				nvidia,emc-auto-cal-config = <0xa1430000>;
				nvidia,emc-auto-cal-config2 = <0x00>;
				nvidia,emc-auto-cal-config3 = <0x00>;
				nvidia,emc-auto-cal-interval = <0x1fffff>;
				nvidia,emc-bgbias-ctl0 = <0x08>;
				nvidia,emc-cfg = <0xf3200000>;
				nvidia,emc-cfg-2 = <0x8c7>;
				nvidia,emc-ctt-term-ctrl = <0x802>;
				nvidia,emc-mode-1 = <0x10083>;
				nvidia,emc-mode-2 = <0x20004>;
				nvidia,emc-mode-4 = <0x800b0000>;
				nvidia,emc-mode-reset = <0x00>;
				nvidia,emc-mrs-wait-cnt = <0x880011>;
				nvidia,emc-sel-dpd-ctrl = <0x4013c>;
				nvidia,emc-xm2dqspadctrl2 = <0x130b018>;
				nvidia,emc-zcal-cnt-long = <0x15>;
				nvidia,emc-zcal-interval = <0x64000>;
				nvidia,emc-configuration = <0x08 0x11 0x00 0x05 0x02 0x07 0x08 0x03 0x0a 0x02 0x02 0x01 0x02 0x00 0x03 0x03 0x06 0x02 0x00 0x05 0x05 0x10000 0x03 0x00 0x00 0x00 0x00 0x04 0x0c 0x0d 0x0f 0x202 0x00 0x80 0x02 0x02 0x02 0x00 0x01 0x0c 0x14 0x14 0x03 0x03 0x03 0x06 0x04 0x03 0x03 0x236 0x00 0x00 0x00 0x1361a296 0x5800a0 0x8000 0x48000 0x48000 0x48000 0x48000 0x48000 0x48000 0x48000 0x48000 0x48000 0x48000 0x48000 0x48000 0x48000 0x48000 0x48000 0x48000 0x00 0x00 0x00 0x00 0x00 0x00 0x00 0x00 0xfc000 0xfc000 0x00 0xfc000 0xfc000 0x00 0x00 0x00 0x00 0x00 0x00 0x00 0x00 0x00 0x00 0x00 0x00 0x00 0x00 0x00 0x00 0x00 0x00 0x00 0x00 0x00 0x00 0x00 0x00 0x00 0xfc000 0xfc000 0xfc000 0xfc000 0xfc00 0xfc00 0xfc00 0xfc00 0x200 0x00 0x100100 0x00 0x00 0x77ffc000 0x404 0x81f1f008 0x7070000 0x3f 0x15ddddd 0x51451400 0x514514 0x514514 0x51451400 0x3f 0x00 0x00 0x31 0x880011 0x00 0x03 0xf3f3 0x8000050e 0x0a>;
			};

			timing-204000000 {
				clock-frequency = <0xc28cb00>;
				nvidia,emc-auto-cal-config = <0xa1430000>;
				nvidia,emc-auto-cal-config2 = <0x00>;
				nvidia,emc-auto-cal-config3 = <0x00>;
				nvidia,emc-auto-cal-interval = <0x1fffff>;
				nvidia,emc-bgbias-ctl0 = <0x08>;
				nvidia,emc-cfg = <0xf3200000>;
				nvidia,emc-cfg-2 = <0x8cf>;
				nvidia,emc-ctt-term-ctrl = <0x802>;
				nvidia,emc-mode-1 = <0x10083>;
				nvidia,emc-mode-2 = <0x20004>;
				nvidia,emc-mode-4 = <0x800b0000>;
				nvidia,emc-mode-reset = <0x00>;
				nvidia,emc-mrs-wait-cnt = <0xcc0011>;
				nvidia,emc-sel-dpd-ctrl = <0x4013c>;
				nvidia,emc-xm2dqspadctrl2 = <0x130b018>;
				nvidia,emc-zcal-cnt-long = <0x17>;
				nvidia,emc-zcal-interval = <0x64000>;
				nvidia,emc-configuration = <0x0c 0x1a 0x00 0x08 0x03 0x07 0x08 0x03 0x0a 0x03 0x03 0x02 0x03 0x00 0x02 0x02 0x05 0x03 0x00 0x03 0x07 0x10000 0x04 0x00 0x00 0x00 0x00 0x02 0x0e 0x0f 0x11 0x304 0x00 0xc1 0x02 0x02 0x03 0x00 0x01 0x0c 0x1d 0x1d 0x03 0x04 0x03 0x09 0x05 0x03 0x03 0x351 0x00 0x00 0x00 0x1361a296 0x5800a0 0x8000 0x48000 0x48000 0x48000 0x48000 0x48000 0x48000 0x48000 0x48000 0x48000 0x48000 0x48000 0x48000 0x48000 0x48000 0x48000 0x48000 0x00 0x00 0x00 0x00 0x00 0x00 0x00 0x00 0x80000 0x80000 0x00 0x80000 0x80000 0x00 0x00 0x00 0x00 0x00 0x00 0x00 0x00 0x00 0x00 0x00 0x00 0x00 0x00 0x00 0x00 0x00 0x00 0x00 0x00 0x00 0x00 0x00 0x00 0x00 0x90000 0x90000 0x90000 0x90000 0x9000 0x9000 0x9000 0x9000 0x200 0x00 0x100100 0x00 0x00 0x77ffc000 0x606 0x81f1f008 0x7070000 0x3f 0x15ddddd 0x51451400 0x514514 0x514514 0x51451400 0x3f 0x00 0x00 0x4a 0xcc0011 0x00 0x04 0xd3b3 0x80000713 0x0a>;
			};

			timing-300000000 {
				clock-frequency = <0x11e1a300>;
				nvidia,emc-auto-cal-config = <0xa1430000>;
				nvidia,emc-auto-cal-config2 = <0x00>;
				nvidia,emc-auto-cal-config3 = <0x00>;
				nvidia,emc-auto-cal-interval = <0x1fffff>;
				nvidia,emc-bgbias-ctl0 = <0x00>;
				nvidia,emc-cfg = <0xf3300000>;
				nvidia,emc-cfg-2 = <0x8d7>;
				nvidia,emc-ctt-term-ctrl = <0x802>;
				nvidia,emc-mode-1 = <0x10083>;
				nvidia,emc-mode-2 = <0x20004>;
				nvidia,emc-mode-4 = <0x800b0000>;
				nvidia,emc-mode-reset = <0x00>;
				nvidia,emc-mrs-wait-cnt = <0x12c0011>;
				nvidia,emc-sel-dpd-ctrl = <0x4013c>;
				nvidia,emc-xm2dqspadctrl2 = <0x1231239>;
				nvidia,emc-zcal-cnt-long = <0x1f>;
				nvidia,emc-zcal-interval = <0x64000>;
				nvidia,emc-configuration = <0x11 0x26 0x00 0x0c 0x05 0x07 0x08 0x03 0x0a 0x05 0x05 0x02 0x03 0x00 0x02 0x02 0x06 0x03 0x00 0x03 0x08 0x30000 0x04 0x00 0x00 0x00 0x00 0x02 0x0f 0x12 0x14 0x46e 0x00 0x11b 0x02 0x02 0x05 0x00 0x01 0x0c 0x2a 0x2a 0x03 0x05 0x03 0x0d 0x07 0x03 0x03 0x4e0 0x00 0x00 0x00 0x1361a096 0x5800a0 0x8000 0x20000 0x20000 0x20000 0x20000 0x20000 0x20000 0x20000 0x20000 0x20000 0x20000 0x20000 0x20000 0x20000 0x20000 0x20000 0x20000 0x00 0x00 0x00 0x00 0x00 0x00 0x00 0x00 0x50000 0x50000 0x00 0x50000 0x50000 0x00 0x00 0x00 0x00 0x00 0x00 0x00 0x00 0x00 0x00 0x00 0x00 0x00 0x00 0x00 0x00 0x00 0x00 0x00 0x00 0x00 0x00 0x00 0x00 0x00 0x60000 0x60000 0x60000 0x60000 0x6000 0x6000 0x6000 0x6000 0x200 0x00 0x100100 0x00 0x00 0x77ffc000 0x606 0x81f1f008 0x7070000 0x3f 0x15ddddd 0x51451420 0x514514 0x514514 0x51451400 0x3f 0x00 0x00 0x6c 0x12c0011 0x00 0x04 0x52a3 0x800009ed 0x0b>;
			};

			timing-396000000 {
				clock-frequency = <0x179a7b00>;
				nvidia,emc-auto-cal-config = <0xa1430000>;
				nvidia,emc-auto-cal-config2 = <0x00>;
				nvidia,emc-auto-cal-config3 = <0x00>;
				nvidia,emc-auto-cal-interval = <0x1fffff>;
				nvidia,emc-bgbias-ctl0 = <0x00>;
				nvidia,emc-cfg = <0xf3300000>;
				nvidia,emc-cfg-2 = <0x897>;
				nvidia,emc-ctt-term-ctrl = <0x802>;
				nvidia,emc-mode-1 = <0x10083>;
				nvidia,emc-mode-2 = <0x20004>;
				nvidia,emc-mode-4 = <0x800b0000>;
				nvidia,emc-mode-reset = <0x00>;
				nvidia,emc-mrs-wait-cnt = <0x18c0011>;
				nvidia,emc-sel-dpd-ctrl = <0x4001c>;
				nvidia,emc-xm2dqspadctrl2 = <0x1231239>;
				nvidia,emc-zcal-cnt-long = <0x28>;
				nvidia,emc-zcal-interval = <0x64000>;
				nvidia,emc-configuration = <0x17 0x33 0x00 0x10 0x07 0x08 0x08 0x03 0x0a 0x07 0x07 0x03 0x03 0x00 0x02 0x02 0x06 0x03 0x00 0x02 0x09 0x30000 0x04 0x00 0x00 0x00 0x00 0x01 0x10 0x12 0x14 0x5d9 0x00 0x176 0x02 0x02 0x07 0x00 0x01 0x0e 0x38 0x38 0x03 0x06 0x03 0x12 0x09 0x03 0x03 0x670 0x00 0x00 0x00 0x1361a096 0x5800a0 0x8000 0x20000 0x20000 0x20000 0x20000 0x20000 0x20000 0x20000 0x20000 0x20000 0x20000 0x20000 0x20000 0x20000 0x20000 0x20000 0x20000 0x00 0x00 0x00 0x00 0x00 0x00 0x00 0x00 0x50000 0x50000 0x00 0x50000 0x50000 0x00 0x00 0x00 0x00 0x00 0x00 0x00 0x00 0x00 0x00 0x00 0x00 0x00 0x00 0x00 0x00 0x00 0x00 0x00 0x00 0x00 0x00 0x00 0x00 0x00 0x40000 0x40000 0x40000 0x40000 0x4000 0x4000 0x4000 0x4000 0x200 0x00 0x100100 0x00 0x00 0x77ffc000 0x606 0x81f1f008 0x7070000 0x3f 0x15ddddd 0x51451420 0x514514 0x514514 0x51451400 0x3f 0x00 0x00 0x8f 0x18c0011 0x00 0x04 0x52a3 0x80000cc7 0x0b>;
			};

			timing-528000000 {
				clock-frequency = <0x1f78a400>;
				nvidia,emc-auto-cal-config = <0xa1430000>;
				nvidia,emc-auto-cal-config2 = <0x00>;
				nvidia,emc-auto-cal-config3 = <0x00>;
				nvidia,emc-auto-cal-interval = <0x1fffff>;
				nvidia,emc-bgbias-ctl0 = <0x00>;
				nvidia,emc-cfg = <0xf3300000>;
				nvidia,emc-cfg-2 = <0x89f>;
				nvidia,emc-ctt-term-ctrl = <0x802>;
				nvidia,emc-mode-1 = <0x100c3>;
				nvidia,emc-mode-2 = <0x20006>;
				nvidia,emc-mode-4 = <0x800b0000>;
				nvidia,emc-mode-reset = <0x00>;
				nvidia,emc-mrs-wait-cnt = <0x2100013>;
				nvidia,emc-sel-dpd-ctrl = <0x4001c>;
				nvidia,emc-xm2dqspadctrl2 = <0x123123d>;
				nvidia,emc-zcal-cnt-long = <0x34>;
				nvidia,emc-zcal-interval = <0x64000>;
				nvidia,emc-configuration = <0x1f 0x44 0x00 0x16 0x09 0x09 0x09 0x03 0x0d 0x09 0x09 0x05 0x04 0x00 0x02 0x02 0x08 0x03 0x00 0x03 0x0a 0x50000 0x04 0x00 0x00 0x00 0x00 0x02 0x11 0x15 0x17 0x7cd 0x00 0x1f3 0x03 0x03 0x09 0x00 0x01 0x11 0x4a 0x4a 0x04 0x08 0x04 0x19 0x0c 0x03 0x03 0x895 0x00 0x00 0x00 0x1361a096 0xe01200b9 0x8000 0x0a 0x0a 0x0a 0x0a 0x0a 0x0a 0x0a 0x0a 0x0a 0x0a 0x0a 0x0a 0x0a 0x0a 0x0a 0x0a 0x00 0x00 0x00 0x00 0x00 0x00 0x00 0x00 0x10 0x10 0x00 0x10 0x10 0x00 0x00 0x00 0x00 0x00 0x00 0x00 0x00 0x00 0x00 0x00 0x00 0x00 0x00 0x00 0x00 0x00 0x00 0x00 0x00 0x00 0x00 0x00 0x00 0x00 0x0c 0x0c 0x0c 0x0c 0x0c 0x0c 0x0c 0x0c 0x220 0x00 0x100100 0x00 0x00 0x77ffc004 0x505 0x81f1f008 0x7070000 0x3f 0x15ddddd 0x51451420 0x514514 0x514514 0x51451400 0x3f 0x00 0x00 0xbf 0x2100013 0x00 0x04 0x42a0 0x800010b3 0x0d>;
			};

			timing-600000000 {
				clock-frequency = <0x23c34600>;
				nvidia,emc-auto-cal-config = <0xa1430000>;
				nvidia,emc-auto-cal-config2 = <0x00>;
				nvidia,emc-auto-cal-config3 = <0x00>;
				nvidia,emc-auto-cal-interval = <0x1fffff>;
				nvidia,emc-bgbias-ctl0 = <0x00>;
				nvidia,emc-cfg = <0xf3300000>;
				nvidia,emc-cfg-2 = <0x89f>;
				nvidia,emc-ctt-term-ctrl = <0x802>;
				nvidia,emc-mode-1 = <0x100e3>;
				nvidia,emc-mode-2 = <0x20007>;
				nvidia,emc-mode-4 = <0x800b0000>;
				nvidia,emc-mode-reset = <0x00>;
				nvidia,emc-mrs-wait-cnt = <0x2580014>;
				nvidia,emc-sel-dpd-ctrl = <0x4001c>;
				nvidia,emc-xm2dqspadctrl2 = <0x121103d>;
				nvidia,emc-zcal-cnt-long = <0x3a>;
				nvidia,emc-zcal-interval = <0x64000>;
				nvidia,emc-configuration = <0x23 0x4d 0x00 0x19 0x0a 0x0a 0x0b 0x04 0x0f 0x0a 0x0a 0x05 0x04 0x00 0x04 0x04 0x0a 0x04 0x00 0x03 0x0d 0x70000 0x05 0x00 0x00 0x00 0x00 0x02 0x14 0x18 0x1a 0x8e4 0x00 0x239 0x04 0x04 0x0a 0x00 0x01 0x13 0x54 0x54 0x05 0x09 0x05 0x1c 0x0d 0x03 0x03 0x9c1 0x00 0x00 0x00 0x1361a096 0xe00e00b9 0x8000 0x08 0x08 0x08 0x08 0x08 0x08 0x08 0x08 0x08 0x08 0x08 0x08 0x08 0x08 0x08 0x08 0x00 0x00 0x00 0x00 0x00 0x00 0x00 0x00 0x10 0x10 0x00 0x10 0x10 0x00 0x00 0x00 0x00 0x00 0x00 0x00 0x00 0x00 0x00 0x00 0x00 0x00 0x00 0x00 0x00 0x00 0x00 0x00 0x00 0x00 0x00 0x00 0x00 0x00 0x0b 0x0b 0x0b 0x0b 0x0b 0x0b 0x0b 0x0b 0x220 0x00 0x100100 0x00 0x00 0x77ffc004 0x606 0x81f1f008 0x7070000 0x3f 0x15ddddd 0x51451420 0x514514 0x514514 0x51451400 0x3f 0x00 0x00 0xd8 0x2580014 0x00 0x05 0x40a0 0x800012d7 0x10>;
			};

			timing-792000000 {
				clock-frequency = <0x2f34f600>;
				nvidia,emc-auto-cal-config = <0xa1430404>;
				nvidia,emc-auto-cal-config2 = <0x00>;
				nvidia,emc-auto-cal-config3 = <0x00>;
				nvidia,emc-auto-cal-interval = <0x1fffff>;
				nvidia,emc-bgbias-ctl0 = <0x00>;
				nvidia,emc-cfg = <0xf3300000>;
				nvidia,emc-cfg-2 = <0x89f>;
				nvidia,emc-ctt-term-ctrl = <0x802>;
				nvidia,emc-mode-1 = <0x10043>;
				nvidia,emc-mode-2 = <0x2001a>;
				nvidia,emc-mode-4 = <0x800b0000>;
				nvidia,emc-mode-reset = <0x00>;
				nvidia,emc-mrs-wait-cnt = <0x3180017>;
				nvidia,emc-sel-dpd-ctrl = <0x4001c>;
				nvidia,emc-xm2dqspadctrl2 = <0x120103d>;
				nvidia,emc-zcal-cnt-long = <0x4c>;
				nvidia,emc-zcal-interval = <0x64000>;
				nvidia,emc-configuration = <0x2f 0x66 0x00 0x21 0x0e 0x0d 0x0d 0x05 0x13 0x0e 0x0e 0x07 0x04 0x00 0x05 0x05 0x0e 0x04 0x00 0x05 0x0f 0xb0000 0x06 0x00 0x00 0x00 0x00 0x04 0x16 0x1d 0x1f 0xbd1 0x00 0x2f4 0x05 0x05 0x0e 0x00 0x01 0x17 0x6f 0x6f 0x06 0x0c 0x06 0x26 0x11 0x03 0x03 0xcdf 0x00 0x00 0x00 0x1361a096 0xe00700b9 0x8000 0x05 0x05 0x05 0x05 0x05 0x05 0x05 0x05 0x05 0x05 0x05 0x05 0x05 0x05 0x05 0x05 0x00 0x00 0x00 0x00 0x00 0x00 0x00 0x00 0x4014 0x4014 0x00 0x4014 0x4014 0x00 0x00 0x00 0x00 0x00 0x00 0x00 0x00 0x00 0x00 0x00 0x00 0x00 0x00 0x00 0x00 0x00 0x00 0x00 0x00 0x00 0x00 0x00 0x00 0x00 0x09 0x09 0x09 0x09 0x09 0x09 0x09 0x09 0x220 0x00 0x100100 0x00 0x00 0x77ffc004 0x606 0x81f1f008 0x7070000 0x00 0x15ddddd 0x59659620 0x492492 0x492492 0x59659600 0x3f 0x00 0x00 0x11e 0x3180017 0x00 0x06 0x4080 0x8000188b 0x14>;
			};

			timing-924000000 {
				clock-frequency = <0x37131f00>;
				nvidia,emc-auto-cal-config = <0xa1430808>;
				nvidia,emc-auto-cal-config2 = <0x00>;
				nvidia,emc-auto-cal-config3 = <0x00>;
				nvidia,emc-auto-cal-interval = <0x1fffff>;
				nvidia,emc-bgbias-ctl0 = <0x00>;
				nvidia,emc-cfg = <0xf3300000>;
				nvidia,emc-cfg-2 = <0x89f>;
				nvidia,emc-ctt-term-ctrl = <0x802>;
				nvidia,emc-mode-1 = <0x10083>;
				nvidia,emc-mode-2 = <0x2001c>;
				nvidia,emc-mode-4 = <0x800b0000>;
				nvidia,emc-mode-reset = <0x00>;
				nvidia,emc-mrs-wait-cnt = <0x39c0019>;
				nvidia,emc-sel-dpd-ctrl = <0x4001c>;
				nvidia,emc-xm2dqspadctrl2 = <0x120103d>;
				nvidia,emc-zcal-cnt-long = <0x58>;
				nvidia,emc-zcal-interval = <0x64000>;
				nvidia,emc-configuration = <0x37 0x78 0x00 0x26 0x10 0x0f 0x10 0x06 0x17 0x10 0x10 0x09 0x05 0x00 0x07 0x07 0x10 0x05 0x00 0x05 0x12 0xd0000 0x07 0x00 0x00 0x00 0x00 0x04 0x19 0x20 0x22 0xdd4 0x00 0x375 0x06 0x06 0x10 0x00 0x01 0x1b 0x82 0x82 0x07 0x0e 0x07 0x2d 0x14 0x03 0x03 0xf04 0x00 0x00 0x00 0x1361a896 0xe00400b9 0x8000 0x05 0x07 0x07 0x05 0x03 0x05 0x05 0x05 0x05 0x07 0x07 0x05 0x03 0x05 0x05 0x05 0x00 0x00 0x00 0x00 0x00 0x00 0x00 0x00 0x800e 0x800e 0x00 0x800e 0x800e 0x00 0x00 0x00 0x00 0x00 0x00 0x00 0x00 0x00 0x00 0x00 0x00 0x00 0x00 0x00 0x00 0x00 0x00 0x00 0x00 0x00 0x00 0x00 0x00 0x00 0x07 0x07 0x07 0x07 0x07 0x07 0x07 0x07 0x220 0x00 0x100100 0x00 0x00 0x77ffc004 0x404 0x81f1f008 0x7070000 0x00 0x15ddddd 0x55555520 0x514514 0x514514 0x55555500 0x3f 0x00 0x00 0x14d 0x39c0019 0x00 0x07 0x4080 0x80001c77 0x17>;
			};
		};

		emc-timings-2 {
			nvidia,ram-code = <0x02>;

			timing-12750000 {
				clock-frequency = <0xc28cb0>;
				nvidia,emc-auto-cal-config = <0xa1430000>;
				nvidia,emc-auto-cal-config2 = <0x00>;
				nvidia,emc-auto-cal-config3 = <0x00>;
				nvidia,emc-auto-cal-interval = <0x1fffff>;
				nvidia,emc-bgbias-ctl0 = <0x08>;
				nvidia,emc-cfg = <0xf3200000>;
				nvidia,emc-cfg-2 = <0x8c7>;
				nvidia,emc-ctt-term-ctrl = <0x802>;
				nvidia,emc-mode-1 = <0x10083>;
				nvidia,emc-mode-2 = <0x20004>;
				nvidia,emc-mode-4 = <0x800b0000>;
				nvidia,emc-mode-reset = <0x00>;
				nvidia,emc-mrs-wait-cnt = <0xd0011>;
				nvidia,emc-sel-dpd-ctrl = <0x4013c>;
				nvidia,emc-xm2dqspadctrl2 = <0x130b018>;
				nvidia,emc-zcal-cnt-long = <0x15>;
				nvidia,emc-zcal-interval = <0x64000>;
				nvidia,emc-configuration = <0x00 0x03 0x00 0x02 0x02 0x06 0x08 0x03 0x0a 0x02 0x02 0x01 0x02 0x00 0x03 0x03 0x06 0x02 0x00 0x05 0x05 0x10000 0x03 0x00 0x00 0x00 0x00 0x04 0x0c 0x0d 0x0f 0x30 0x00 0x0c 0x02 0x02 0x02 0x00 0x01 0x0c 0x03 0x02 0x03 0x03 0x03 0x06 0x04 0x03 0x03 0x36 0x00 0x00 0x00 0x1361a296 0x5800a0 0x8000 0x80000 0x80000 0x80000 0x80000 0x80000 0x80000 0x80000 0x80000 0x80000 0x80000 0x80000 0x80000 0x80000 0x80000 0x80000 0x80000 0x00 0x00 0x00 0x00 0x00 0x00 0x00 0x00 0xfc000 0xfc000 0x00 0xfc000 0xfc000 0x00 0x00 0x00 0x00 0x00 0x00 0x00 0x00 0x00 0x00 0x00 0x00 0x00 0x00 0x00 0x00 0x00 0x00 0x00 0x00 0x00 0x00 0x00 0x00 0x00 0xfc000 0xfc000 0xfc000 0xfc000 0xfc00 0xfc00 0xfc00 0xfc00 0x200 0x00 0x100100 0x00 0x00 0x77ffc000 0x404 0x81f1f008 0x7070000 0x3f 0x15ddddd 0x51451400 0x514514 0x514514 0x51451400 0x3f 0x00 0x00 0x11 0xd0011 0x00 0x03 0xf3f3 0x80000164 0x0a>;
			};

			timing-20400000 {
				clock-frequency = <0x1374780>;
				nvidia,emc-auto-cal-config = <0xa1430000>;
				nvidia,emc-auto-cal-config2 = <0x00>;
				nvidia,emc-auto-cal-config3 = <0x00>;
				nvidia,emc-auto-cal-interval = <0x1fffff>;
				nvidia,emc-bgbias-ctl0 = <0x08>;
				nvidia,emc-cfg = <0xf3200000>;
				nvidia,emc-cfg-2 = <0x8c7>;
				nvidia,emc-ctt-term-ctrl = <0x802>;
				nvidia,emc-mode-1 = <0x10083>;
				nvidia,emc-mode-2 = <0x20004>;
				nvidia,emc-mode-4 = <0x800b0000>;
				nvidia,emc-mode-reset = <0x00>;
				nvidia,emc-mrs-wait-cnt = <0x150011>;
				nvidia,emc-sel-dpd-ctrl = <0x4013c>;
				nvidia,emc-xm2dqspadctrl2 = <0x130b018>;
				nvidia,emc-zcal-cnt-long = <0x15>;
				nvidia,emc-zcal-interval = <0x64000>;
				nvidia,emc-configuration = <0x01 0x03 0x00 0x02 0x02 0x06 0x08 0x03 0x0a 0x02 0x02 0x01 0x02 0x00 0x03 0x03 0x06 0x02 0x00 0x05 0x05 0x10000 0x03 0x00 0x00 0x00 0x00 0x04 0x0c 0x0d 0x0f 0x4d 0x00 0x13 0x02 0x02 0x02 0x00 0x01 0x0c 0x03 0x03 0x03 0x03 0x03 0x06 0x04 0x03 0x03 0x55 0x00 0x00 0x00 0x1361a296 0x5800a0 0x8000 0x80000 0x80000 0x80000 0x80000 0x80000 0x80000 0x80000 0x80000 0x80000 0x80000 0x80000 0x80000 0x80000 0x80000 0x80000 0x80000 0x00 0x00 0x00 0x00 0x00 0x00 0x00 0x00 0xfc000 0xfc000 0x00 0xfc000 0xfc000 0x00 0x00 0x00 0x00 0x00 0x00 0x00 0x00 0x00 0x00 0x00 0x00 0x00 0x00 0x00 0x00 0x00 0x00 0x00 0x00 0x00 0x00 0x00 0x00 0x00 0xfc000 0xfc000 0xfc000 0xfc000 0xfc00 0xfc00 0xfc00 0xfc00 0x200 0x00 0x100100 0x00 0x00 0x77ffc000 0x404 0x81f1f008 0x7070000 0x3f 0x15ddddd 0x51451400 0x514514 0x514514 0x51451400 0x3f 0x00 0x00 0x11 0x150011 0x00 0x03 0xf3f3 0x8000019f 0x0a>;
			};

			timing-40800000 {
				clock-frequency = <0x26e8f00>;
				nvidia,emc-auto-cal-config = <0xa1430000>;
				nvidia,emc-auto-cal-config2 = <0x00>;
				nvidia,emc-auto-cal-config3 = <0x00>;
				nvidia,emc-auto-cal-interval = <0x1fffff>;
				nvidia,emc-bgbias-ctl0 = <0x08>;
				nvidia,emc-cfg = <0xf3200000>;
				nvidia,emc-cfg-2 = <0x8c7>;
				nvidia,emc-ctt-term-ctrl = <0x802>;
				nvidia,emc-mode-1 = <0x10083>;
				nvidia,emc-mode-2 = <0x20004>;
				nvidia,emc-mode-4 = <0x800b0000>;
				nvidia,emc-mode-reset = <0x00>;
				nvidia,emc-mrs-wait-cnt = <0x290011>;
				nvidia,emc-sel-dpd-ctrl = <0x4013c>;
				nvidia,emc-xm2dqspadctrl2 = <0x130b018>;
				nvidia,emc-zcal-cnt-long = <0x15>;
				nvidia,emc-zcal-interval = <0x64000>;
				nvidia,emc-configuration = <0x02 0x05 0x00 0x02 0x02 0x06 0x08 0x03 0x0a 0x02 0x02 0x01 0x02 0x00 0x03 0x03 0x06 0x02 0x00 0x05 0x05 0x10000 0x03 0x00 0x00 0x00 0x00 0x04 0x0c 0x0d 0x0f 0x9a 0x00 0x26 0x02 0x02 0x02 0x00 0x01 0x0c 0x06 0x06 0x03 0x03 0x03 0x06 0x04 0x03 0x03 0xaa 0x00 0x00 0x00 0x1361a296 0x5800a0 0x8000 0x80000 0x80000 0x80000 0x80000 0x80000 0x80000 0x80000 0x80000 0x80000 0x80000 0x80000 0x80000 0x80000 0x80000 0x80000 0x80000 0x00 0x00 0x00 0x00 0x00 0x00 0x00 0x00 0xfc000 0xfc000 0x00 0xfc000 0xfc000 0x00 0x00 0x00 0x00 0x00 0x00 0x00 0x00 0x00 0x00 0x00 0x00 0x00 0x00 0x00 0x00 0x00 0x00 0x00 0x00 0x00 0x00 0x00 0x00 0x00 0xfc000 0xfc000 0xfc000 0xfc000 0xfc00 0xfc00 0xfc00 0xfc00 0x200 0x00 0x100100 0x00 0x00 0x77ffc000 0x404 0x81f1f008 0x7070000 0x3f 0x15ddddd 0x51451400 0x514514 0x514514 0x51451400 0x3f 0x00 0x00 0x11 0x290011 0x00 0x03 0xf3f3 0x8000023a 0x0a>;
			};

			timing-68000000 {
				clock-frequency = <0x40d9900>;
				nvidia,emc-auto-cal-config = <0xa1430000>;
				nvidia,emc-auto-cal-config2 = <0x00>;
				nvidia,emc-auto-cal-config3 = <0x00>;
				nvidia,emc-auto-cal-interval = <0x1fffff>;
				nvidia,emc-bgbias-ctl0 = <0x08>;
				nvidia,emc-cfg = <0xf3200000>;
				nvidia,emc-cfg-2 = <0x8c7>;
				nvidia,emc-ctt-term-ctrl = <0x802>;
				nvidia,emc-mode-1 = <0x10083>;
				nvidia,emc-mode-2 = <0x20004>;
				nvidia,emc-mode-4 = <0x800b0000>;
				nvidia,emc-mode-reset = <0x00>;
				nvidia,emc-mrs-wait-cnt = <0x440011>;
				nvidia,emc-sel-dpd-ctrl = <0x4013c>;
				nvidia,emc-xm2dqspadctrl2 = <0x130b018>;
				nvidia,emc-zcal-cnt-long = <0x15>;
				nvidia,emc-zcal-interval = <0x64000>;
				nvidia,emc-configuration = <0x04 0x08 0x00 0x02 0x02 0x06 0x08 0x03 0x0a 0x02 0x02 0x01 0x02 0x00 0x03 0x03 0x06 0x02 0x00 0x05 0x05 0x10000 0x03 0x00 0x00 0x00 0x00 0x04 0x0c 0x0d 0x0f 0x101 0x00 0x40 0x02 0x02 0x02 0x00 0x01 0x0c 0x0a 0x0a 0x03 0x03 0x03 0x06 0x04 0x03 0x03 0x11b 0x00 0x00 0x00 0x1361a296 0x5800a0 0x8000 0x80000 0x80000 0x80000 0x80000 0x80000 0x80000 0x80000 0x80000 0x80000 0x80000 0x80000 0x80000 0x80000 0x80000 0x80000 0x80000 0x00 0x00 0x00 0x00 0x00 0x00 0x00 0x00 0xfc000 0xfc000 0x00 0xfc000 0xfc000 0x00 0x00 0x00 0x00 0x00 0x00 0x00 0x00 0x00 0x00 0x00 0x00 0x00 0x00 0x00 0x00 0x00 0x00 0x00 0x00 0x00 0x00 0x00 0x00 0x00 0xfc000 0xfc000 0xfc000 0xfc000 0xfc00 0xfc00 0xfc00 0xfc00 0x200 0x00 0x100100 0x00 0x00 0x77ffc000 0x404 0x81f1f008 0x7070000 0x3f 0x15ddddd 0x51451400 0x514514 0x514514 0x51451400 0x3f 0x00 0x00 0x19 0x440011 0x00 0x03 0xf3f3 0x80000309 0x0a>;
			};

			timing-102000000 {
				clock-frequency = <0x6146580>;
				nvidia,emc-auto-cal-config = <0xa1430000>;
				nvidia,emc-auto-cal-config2 = <0x00>;
				nvidia,emc-auto-cal-config3 = <0x00>;
				nvidia,emc-auto-cal-interval = <0x1fffff>;
				nvidia,emc-bgbias-ctl0 = <0x08>;
				nvidia,emc-cfg = <0xf3200000>;
				nvidia,emc-cfg-2 = <0x8c7>;
				nvidia,emc-ctt-term-ctrl = <0x802>;
				nvidia,emc-mode-1 = <0x10083>;
				nvidia,emc-mode-2 = <0x20004>;
				nvidia,emc-mode-4 = <0x800b0000>;
				nvidia,emc-mode-reset = <0x00>;
				nvidia,emc-mrs-wait-cnt = <0x660011>;
				nvidia,emc-sel-dpd-ctrl = <0x4013c>;
				nvidia,emc-xm2dqspadctrl2 = <0x130b018>;
				nvidia,emc-zcal-cnt-long = <0x15>;
				nvidia,emc-zcal-interval = <0x64000>;
				nvidia,emc-configuration = <0x06 0x0d 0x00 0x04 0x02 0x06 0x08 0x03 0x0a 0x02 0x02 0x01 0x02 0x00 0x03 0x03 0x06 0x02 0x00 0x05 0x05 0x10000 0x03 0x00 0x00 0x00 0x00 0x04 0x0c 0x0d 0x0f 0x182 0x00 0x60 0x02 0x02 0x02 0x00 0x01 0x0c 0x0f 0x0f 0x03 0x03 0x03 0x06 0x04 0x03 0x03 0x1a9 0x00 0x00 0x00 0x1361a296 0x5800a0 0x8000 0x80000 0x80000 0x80000 0x80000 0x80000 0x80000 0x80000 0x80000 0x80000 0x80000 0x80000 0x80000 0x80000 0x80000 0x80000 0x80000 0x00 0x00 0x00 0x00 0x00 0x00 0x00 0x00 0xfc000 0xfc000 0x00 0xfc000 0xfc000 0x00 0x00 0x00 0x00 0x00 0x00 0x00 0x00 0x00 0x00 0x00 0x00 0x00 0x00 0x00 0x00 0x00 0x00 0x00 0x00 0x00 0x00 0x00 0x00 0x00 0xfc000 0xfc000 0xfc000 0xfc000 0xfc00 0xfc00 0xfc00 0xfc00 0x200 0x00 0x100100 0x00 0x00 0x77ffc000 0x404 0x81f1f008 0x7070000 0x3f 0x15ddddd 0x51451400 0x514514 0x514514 0x51451400 0x3f 0x00 0x00 0x25 0x660011 0x00 0x03 0xf3f3 0x8000040b 0x0a>;
			};

			timing-136000000 {
				clock-frequency = <0x81b3200>;
				nvidia,emc-auto-cal-config = <0xa1430000>;
				nvidia,emc-auto-cal-config2 = <0x00>;
				nvidia,emc-auto-cal-config3 = <0x00>;
				nvidia,emc-auto-cal-interval = <0x1fffff>;
				nvidia,emc-bgbias-ctl0 = <0x08>;
				nvidia,emc-cfg = <0xf3200000>;
				nvidia,emc-cfg-2 = <0x8c7>;
				nvidia,emc-ctt-term-ctrl = <0x802>;
				nvidia,emc-mode-1 = <0x10083>;
				nvidia,emc-mode-2 = <0x20004>;
				nvidia,emc-mode-4 = <0x800b0000>;
				nvidia,emc-mode-reset = <0x00>;
				nvidia,emc-mrs-wait-cnt = <0x880011>;
				nvidia,emc-sel-dpd-ctrl = <0x4013c>;
				nvidia,emc-xm2dqspadctrl2 = <0x130b018>;
				nvidia,emc-zcal-cnt-long = <0x15>;
				nvidia,emc-zcal-interval = <0x64000>;
				nvidia,emc-configuration = <0x08 0x11 0x00 0x05 0x02 0x07 0x08 0x03 0x0a 0x02 0x02 0x01 0x02 0x00 0x03 0x03 0x06 0x02 0x00 0x05 0x05 0x10000 0x03 0x00 0x00 0x00 0x00 0x04 0x0c 0x0d 0x0f 0x202 0x00 0x80 0x02 0x02 0x02 0x00 0x01 0x0c 0x14 0x14 0x03 0x03 0x03 0x06 0x04 0x03 0x03 0x236 0x00 0x00 0x00 0x1361a296 0x5800a0 0x8000 0x80000 0x80000 0x80000 0x80000 0x80000 0x80000 0x80000 0x80000 0x80000 0x80000 0x80000 0x80000 0x80000 0x80000 0x80000 0x80000 0x00 0x00 0x00 0x00 0x00 0x00 0x00 0x00 0xfc000 0xfc000 0x00 0xfc000 0xfc000 0x00 0x00 0x00 0x00 0x00 0x00 0x00 0x00 0x00 0x00 0x00 0x00 0x00 0x00 0x00 0x00 0x00 0x00 0x00 0x00 0x00 0x00 0x00 0x00 0x00 0xfc000 0xfc000 0xfc000 0xfc000 0xfc00 0xfc00 0xfc00 0xfc00 0x200 0x00 0x100100 0x00 0x00 0x77ffc000 0x404 0x81f1f008 0x7070000 0x3f 0x15ddddd 0x51451400 0x514514 0x514514 0x51451400 0x3f 0x00 0x00 0x31 0x880011 0x00 0x03 0xf3f3 0x8000050e 0x0a>;
			};

			timing-204000000 {
				clock-frequency = <0xc28cb00>;
				nvidia,emc-auto-cal-config = <0xa1430000>;
				nvidia,emc-auto-cal-config2 = <0x00>;
				nvidia,emc-auto-cal-config3 = <0x00>;
				nvidia,emc-auto-cal-interval = <0x1fffff>;
				nvidia,emc-bgbias-ctl0 = <0x08>;
				nvidia,emc-cfg = <0xf3200000>;
				nvidia,emc-cfg-2 = <0x8cf>;
				nvidia,emc-ctt-term-ctrl = <0x802>;
				nvidia,emc-mode-1 = <0x10083>;
				nvidia,emc-mode-2 = <0x20004>;
				nvidia,emc-mode-4 = <0x800b0000>;
				nvidia,emc-mode-reset = <0x00>;
				nvidia,emc-mrs-wait-cnt = <0xcc0011>;
				nvidia,emc-sel-dpd-ctrl = <0x4013c>;
				nvidia,emc-xm2dqspadctrl2 = <0x130b018>;
				nvidia,emc-zcal-cnt-long = <0x17>;
				nvidia,emc-zcal-interval = <0x64000>;
				nvidia,emc-configuration = <0x0c 0x1a 0x00 0x08 0x03 0x07 0x08 0x03 0x0a 0x03 0x03 0x02 0x03 0x00 0x02 0x02 0x05 0x03 0x00 0x03 0x07 0x10000 0x04 0x00 0x00 0x00 0x00 0x02 0x0e 0x0f 0x11 0x304 0x00 0xc1 0x02 0x02 0x03 0x00 0x01 0x0c 0x1d 0x1d 0x03 0x04 0x03 0x09 0x05 0x03 0x03 0x351 0x00 0x00 0x00 0x1361a296 0x5800a0 0x8000 0x60000 0x60000 0x60000 0x60000 0x60000 0x60000 0x60000 0x60000 0x60000 0x60000 0x60000 0x60000 0x60000 0x60000 0x60000 0x60000 0x00 0x00 0x00 0x00 0x00 0x00 0x00 0x00 0x68000 0x68000 0x00 0x68000 0x68000 0x00 0x00 0x00 0x00 0x00 0x00 0x00 0x00 0x00 0x00 0x00 0x00 0x00 0x00 0x00 0x00 0x00 0x00 0x00 0x00 0x00 0x00 0x00 0x00 0x00 0x68000 0x68000 0x68000 0x68000 0x6800 0x6800 0x6800 0x6800 0x200 0x00 0x100100 0x00 0x00 0x77ffc000 0x606 0x81f1f008 0x7070000 0x3f 0x15ddddd 0x51451400 0x514514 0x514514 0x51451400 0x3f 0x00 0x00 0x4a 0xcc0011 0x00 0x04 0xd3b3 0x80000713 0x0a>;
			};

			timing-300000000 {
				clock-frequency = <0x11e1a300>;
				nvidia,emc-auto-cal-config = <0xa1430000>;
				nvidia,emc-auto-cal-config2 = <0x00>;
				nvidia,emc-auto-cal-config3 = <0x00>;
				nvidia,emc-auto-cal-interval = <0x1fffff>;
				nvidia,emc-bgbias-ctl0 = <0x00>;
				nvidia,emc-cfg = <0xf3300000>;
				nvidia,emc-cfg-2 = <0x8d7>;
				nvidia,emc-ctt-term-ctrl = <0x802>;
				nvidia,emc-mode-1 = <0x10083>;
				nvidia,emc-mode-2 = <0x20004>;
				nvidia,emc-mode-4 = <0x800b0000>;
				nvidia,emc-mode-reset = <0x00>;
				nvidia,emc-mrs-wait-cnt = <0x12c0011>;
				nvidia,emc-sel-dpd-ctrl = <0x4013c>;
				nvidia,emc-xm2dqspadctrl2 = <0x1231239>;
				nvidia,emc-zcal-cnt-long = <0x1f>;
				nvidia,emc-zcal-interval = <0x64000>;
				nvidia,emc-configuration = <0x11 0x26 0x00 0x0c 0x05 0x07 0x08 0x03 0x0a 0x05 0x05 0x02 0x03 0x00 0x02 0x02 0x06 0x03 0x00 0x03 0x08 0x30000 0x04 0x00 0x00 0x00 0x00 0x02 0x0f 0x12 0x14 0x46e 0x00 0x11b 0x02 0x02 0x05 0x00 0x01 0x0c 0x2a 0x2a 0x03 0x05 0x03 0x0d 0x07 0x03 0x03 0x4e0 0x00 0x00 0x00 0x1361a096 0x5800a0 0x8000 0x20000 0x20000 0x20000 0x20000 0x20000 0x20000 0x20000 0x20000 0x20000 0x20000 0x20000 0x20000 0x20000 0x20000 0x20000 0x20000 0x00 0x00 0x00 0x00 0x00 0x00 0x00 0x00 0x58000 0x58000 0x00 0x58000 0x58000 0x00 0x00 0x00 0x00 0x00 0x00 0x00 0x00 0x00 0x00 0x00 0x00 0x00 0x00 0x00 0x00 0x00 0x00 0x00 0x00 0x00 0x00 0x00 0x00 0x00 0x48000 0x48000 0x48000 0x48000 0x4800 0x4800 0x4800 0x4800 0x200 0x00 0x100100 0x00 0x00 0x77ffc000 0x606 0x81f1f008 0x7070000 0x3f 0x15ddddd 0x51451420 0x514514 0x514514 0x51451400 0x3f 0x00 0x00 0x6c 0x12c0011 0x00 0x04 0x52a3 0x800009ed 0x0b>;
			};

			timing-396000000 {
				clock-frequency = <0x179a7b00>;
				nvidia,emc-auto-cal-config = <0xa1430000>;
				nvidia,emc-auto-cal-config2 = <0x00>;
				nvidia,emc-auto-cal-config3 = <0x00>;
				nvidia,emc-auto-cal-interval = <0x1fffff>;
				nvidia,emc-bgbias-ctl0 = <0x00>;
				nvidia,emc-cfg = <0xf3300000>;
				nvidia,emc-cfg-2 = <0x897>;
				nvidia,emc-ctt-term-ctrl = <0x802>;
				nvidia,emc-mode-1 = <0x10083>;
				nvidia,emc-mode-2 = <0x20004>;
				nvidia,emc-mode-4 = <0x800b0000>;
				nvidia,emc-mode-reset = <0x00>;
				nvidia,emc-mrs-wait-cnt = <0x18c0011>;
				nvidia,emc-sel-dpd-ctrl = <0x4001c>;
				nvidia,emc-xm2dqspadctrl2 = <0x1231239>;
				nvidia,emc-zcal-cnt-long = <0x28>;
				nvidia,emc-zcal-interval = <0x64000>;
				nvidia,emc-configuration = <0x17 0x33 0x00 0x10 0x07 0x08 0x08 0x03 0x0a 0x07 0x07 0x03 0x03 0x00 0x02 0x02 0x06 0x03 0x00 0x02 0x09 0x30000 0x04 0x00 0x00 0x00 0x00 0x01 0x10 0x12 0x14 0x5d9 0x00 0x176 0x02 0x02 0x07 0x00 0x01 0x0e 0x38 0x38 0x03 0x06 0x03 0x12 0x09 0x03 0x03 0x670 0x00 0x00 0x00 0x1361a096 0x5800a0 0x8000 0x20000 0x20000 0x20000 0x20000 0x20000 0x20000 0x20000 0x20000 0x20000 0x20000 0x20000 0x20000 0x20000 0x20000 0x20000 0x20000 0x00 0x00 0x00 0x00 0x00 0x00 0x00 0x00 0x58000 0x58000 0x00 0x58000 0x58000 0x00 0x00 0x00 0x00 0x00 0x00 0x00 0x00 0x00 0x00 0x00 0x00 0x00 0x00 0x00 0x00 0x00 0x00 0x00 0x00 0x00 0x00 0x00 0x00 0x00 0x40000 0x40000 0x40000 0x40000 0x4000 0x4000 0x4000 0x4000 0x200 0x00 0x100100 0x00 0x00 0x77ffc000 0x606 0x81f1f008 0x7070000 0x3f 0x15ddddd 0x51451420 0x514514 0x514514 0x51451400 0x3f 0x00 0x00 0x8f 0x18c0011 0x00 0x04 0x52a3 0x80000cc7 0x0b>;
			};

			timing-528000000 {
				clock-frequency = <0x1f78a400>;
				nvidia,emc-auto-cal-config = <0xa1430000>;
				nvidia,emc-auto-cal-config2 = <0x00>;
				nvidia,emc-auto-cal-config3 = <0x00>;
				nvidia,emc-auto-cal-interval = <0x1fffff>;
				nvidia,emc-bgbias-ctl0 = <0x00>;
				nvidia,emc-cfg = <0xf3300000>;
				nvidia,emc-cfg-2 = <0x89f>;
				nvidia,emc-ctt-term-ctrl = <0x802>;
				nvidia,emc-mode-1 = <0x100c3>;
				nvidia,emc-mode-2 = <0x20006>;
				nvidia,emc-mode-4 = <0x800b0000>;
				nvidia,emc-mode-reset = <0x00>;
				nvidia,emc-mrs-wait-cnt = <0x2100013>;
				nvidia,emc-sel-dpd-ctrl = <0x4001c>;
				nvidia,emc-xm2dqspadctrl2 = <0x123123d>;
				nvidia,emc-zcal-cnt-long = <0x34>;
				nvidia,emc-zcal-interval = <0x64000>;
				nvidia,emc-configuration = <0x1f 0x44 0x00 0x16 0x09 0x09 0x09 0x03 0x0d 0x09 0x09 0x05 0x04 0x00 0x02 0x02 0x08 0x03 0x00 0x03 0x0a 0x50000 0x04 0x00 0x00 0x00 0x00 0x02 0x11 0x15 0x17 0x7cd 0x00 0x1f3 0x03 0x03 0x09 0x00 0x01 0x11 0x4a 0x4a 0x04 0x08 0x04 0x19 0x0c 0x03 0x03 0x895 0x00 0x00 0x00 0x1361a096 0xe01200b9 0x8000 0x0a 0x0a 0x0a 0x0a 0x0a 0x0a 0x0a 0x0a 0x0a 0x0a 0x0a 0x0a 0x0a 0x0a 0x0a 0x0a 0x00 0x00 0x00 0x00 0x00 0x00 0x00 0x00 0x10 0x10 0x00 0x10 0x10 0x00 0x00 0x00 0x00 0x00 0x00 0x00 0x00 0x00 0x00 0x00 0x00 0x00 0x00 0x00 0x00 0x00 0x00 0x00 0x00 0x00 0x00 0x00 0x00 0x00 0x0c 0x0c 0x0c 0x0c 0x0c 0x0c 0x0c 0x0c 0x220 0x00 0x100100 0x00 0x00 0x77ffc004 0x505 0x81f1f008 0x7070000 0x3f 0x15ddddd 0x51451420 0x514514 0x514514 0x51451400 0x3f 0x00 0x00 0xbf 0x2100013 0x00 0x04 0x42a0 0x800010b3 0x0d>;
			};

			timing-600000000 {
				clock-frequency = <0x23c34600>;
				nvidia,emc-auto-cal-config = <0xa1430000>;
				nvidia,emc-auto-cal-config2 = <0x00>;
				nvidia,emc-auto-cal-config3 = <0x00>;
				nvidia,emc-auto-cal-interval = <0x1fffff>;
				nvidia,emc-bgbias-ctl0 = <0x00>;
				nvidia,emc-cfg = <0xf3300000>;
				nvidia,emc-cfg-2 = <0x89f>;
				nvidia,emc-ctt-term-ctrl = <0x802>;
				nvidia,emc-mode-1 = <0x100e3>;
				nvidia,emc-mode-2 = <0x20007>;
				nvidia,emc-mode-4 = <0x800b0000>;
				nvidia,emc-mode-reset = <0x00>;
				nvidia,emc-mrs-wait-cnt = <0x2580014>;
				nvidia,emc-sel-dpd-ctrl = <0x4001c>;
				nvidia,emc-xm2dqspadctrl2 = <0x121103d>;
				nvidia,emc-zcal-cnt-long = <0x3a>;
				nvidia,emc-zcal-interval = <0x64000>;
				nvidia,emc-configuration = <0x23 0x4d 0x00 0x19 0x0a 0x0a 0x0b 0x04 0x0f 0x0a 0x0a 0x05 0x04 0x00 0x04 0x04 0x0a 0x04 0x00 0x03 0x0d 0x70000 0x05 0x00 0x00 0x00 0x00 0x02 0x14 0x18 0x1a 0x8e4 0x00 0x239 0x04 0x04 0x0a 0x00 0x01 0x13 0x54 0x54 0x05 0x09 0x05 0x1c 0x0d 0x03 0x03 0x9c0 0x00 0x00 0x00 0x1361a096 0xe00e00b9 0x8000 0x08 0x08 0x08 0x08 0x08 0x08 0x08 0x08 0x08 0x08 0x08 0x08 0x08 0x08 0x08 0x08 0x00 0x00 0x00 0x00 0x00 0x00 0x00 0x00 0x10 0x10 0x00 0x10 0x10 0x00 0x00 0x00 0x00 0x00 0x00 0x00 0x00 0x00 0x00 0x00 0x00 0x00 0x00 0x00 0x00 0x00 0x00 0x00 0x00 0x00 0x00 0x00 0x00 0x00 0x0b 0x0b 0x0b 0x0b 0x0b 0x0b 0x0b 0x0b 0x220 0x00 0x100100 0x00 0x00 0x77ffc004 0x303 0x81f1f008 0x7070000 0x3f 0x15ddddd 0x51451420 0x514514 0x514514 0x51451400 0x3f 0x00 0x00 0xd8 0x2580014 0x00 0x05 0x40a0 0x800012d7 0x10>;
			};

			timing-792000000 {
				clock-frequency = <0x2f34f600>;
				nvidia,emc-auto-cal-config = <0xa1430404>;
				nvidia,emc-auto-cal-config2 = <0x00>;
				nvidia,emc-auto-cal-config3 = <0x00>;
				nvidia,emc-auto-cal-interval = <0x1fffff>;
				nvidia,emc-bgbias-ctl0 = <0x00>;
				nvidia,emc-cfg = <0xf3300000>;
				nvidia,emc-cfg-2 = <0x89f>;
				nvidia,emc-ctt-term-ctrl = <0x802>;
				nvidia,emc-mode-1 = <0x10043>;
				nvidia,emc-mode-2 = <0x2001a>;
				nvidia,emc-mode-4 = <0x800b0000>;
				nvidia,emc-mode-reset = <0x00>;
				nvidia,emc-mrs-wait-cnt = <0x3180017>;
				nvidia,emc-sel-dpd-ctrl = <0x4001c>;
				nvidia,emc-xm2dqspadctrl2 = <0x120103d>;
				nvidia,emc-zcal-cnt-long = <0x4c>;
				nvidia,emc-zcal-interval = <0x64000>;
				nvidia,emc-configuration = <0x2f 0x66 0x00 0x21 0x0e 0x0d 0x0d 0x05 0x13 0x0e 0x0e 0x07 0x04 0x00 0x05 0x05 0x0e 0x04 0x00 0x05 0x0f 0xb0000 0x06 0x00 0x00 0x00 0x00 0x04 0x16 0x1d 0x1f 0xbd1 0x00 0x2f4 0x05 0x05 0x0e 0x00 0x01 0x17 0x6f 0x6f 0x06 0x0c 0x06 0x26 0x11 0x03 0x03 0xcdf 0x00 0x00 0x00 0x1361a096 0xe00700b9 0x8000 0x7f8008 0x7f8008 0x7f8008 0x7f8008 0x7f8008 0x7f8008 0x7f8008 0x7f8008 0x7f8008 0x7f8008 0x7f8008 0x7f8008 0x7f8008 0x7f8008 0x7f8008 0x7f8008 0x00 0x00 0x00 0x00 0x00 0x00 0x00 0x00 0x800f 0x800f 0x00 0x800f 0x800f 0x00 0x00 0x00 0x00 0x00 0x00 0x00 0x00 0x00 0x00 0x00 0x00 0x00 0x00 0x00 0x00 0x00 0x00 0x00 0x00 0x00 0x00 0x00 0x00 0x00 0x0a 0x0a 0x0a 0x0a 0x0a 0x0a 0x0a 0x0a 0x220 0x00 0x100100 0x00 0x00 0x77ffc004 0x303 0x81f1f008 0x7070000 0x00 0x15ddddd 0x49249220 0x492492 0x492492 0x49249200 0x3f 0x00 0x00 0x11e 0x3180017 0x00 0x06 0x4080 0x8000188b 0x14>;
			};

			timing-924000000 {
				clock-frequency = <0x37131f00>;
				nvidia,emc-auto-cal-config = <0xa1430808>;
				nvidia,emc-auto-cal-config2 = <0x00>;
				nvidia,emc-auto-cal-config3 = <0x00>;
				nvidia,emc-auto-cal-interval = <0x1fffff>;
				nvidia,emc-bgbias-ctl0 = <0x00>;
				nvidia,emc-cfg = <0xf3300000>;
				nvidia,emc-cfg-2 = <0x89f>;
				nvidia,emc-ctt-term-ctrl = <0x802>;
				nvidia,emc-mode-1 = <0x10083>;
				nvidia,emc-mode-2 = <0x2001c>;
				nvidia,emc-mode-4 = <0x800b0000>;
				nvidia,emc-mode-reset = <0x00>;
				nvidia,emc-mrs-wait-cnt = <0x39c0019>;
				nvidia,emc-sel-dpd-ctrl = <0x4001c>;
				nvidia,emc-xm2dqspadctrl2 = <0x120103d>;
				nvidia,emc-zcal-cnt-long = <0x58>;
				nvidia,emc-zcal-interval = <0x64000>;
				nvidia,emc-configuration = <0x37 0x78 0x00 0x26 0x10 0x0f 0x10 0x06 0x17 0x10 0x10 0x09 0x05 0x00 0x07 0x07 0x10 0x05 0x00 0x05 0x12 0xd0000 0x07 0x00 0x00 0x00 0x00 0x04 0x19 0x20 0x22 0xdd4 0x00 0x375 0x06 0x06 0x10 0x00 0x01 0x1b 0x82 0x82 0x07 0x0e 0x07 0x2d 0x14 0x03 0x03 0xf04 0x02 0x00 0x00 0x1361a896 0xe00400b9 0x8000 0x05 0x7fc005 0x7fc007 0x05 0x7fc005 0x7fc005 0x7fc006 0x7fc005 0x05 0x7fc005 0x7fc007 0x05 0x7fc005 0x7fc005 0x7fc006 0x7fc005 0x8000 0x8000 0x8000 0x8000 0x8000 0x8000 0x8000 0x8000 0x800e 0x800e 0x00 0x800e 0x800e 0x00 0x00 0x00 0x00 0x00 0x00 0x00 0x00 0x00 0x00 0x00 0x00 0x00 0x00 0x00 0x00 0x00 0x00 0x00 0x00 0x00 0x00 0x00 0x00 0x00 0x0a 0x0a 0x0a 0x0a 0x0a 0x0a 0x0a 0x0a 0x220 0x00 0x100100 0x00 0x00 0x77ffc004 0x303 0x81f1f008 0x7070000 0x00 0x15ddddd 0x59555520 0x554596 0x557594 0x55555500 0x3f 0x00 0x00 0x14d 0x39c0019 0x00 0x07 0x4080 0x80001c77 0x17>;
			};
		};
	};

	sata@70020000 {
		compatible = "nvidia,tegra124-ahci";
		reg = <0x00 0x70027000 0x00 0x2000 0x00 0x70020000 0x00 0x7000>;
		interrupts = <0x00 0x17 0x04>;
		clocks = <0x03 0x7c 0x03 0x7b>;
		clock-names = "sata", "sata-oob";
		resets = <0x03 0x7c 0x03 0x81 0x03 0x7b>;
		reset-names = "sata", "sata-cold", "sata-oob";
		status = "disabled";
	};

	hda@70030000 {
		compatible = "nvidia,tegra132-hda", "nvidia,tegra124-hda", "nvidia,tegra30-hda";
		reg = <0x00 0x70030000 0x00 0x10000>;
		interrupts = <0x00 0x51 0x04>;
		clocks = <0x03 0x7d 0x03 0x80 0x03 0x6f>;
		clock-names = "hda", "hda2hdmi", "hda2codec_2x";
		resets = <0x03 0x7d 0x03 0x80 0x03 0x6f>;
		reset-names = "hda", "hda2hdmi", "hda2codec_2x";
		status = "disabled";
	};

	ccplex-clock@70040000 {
		compatible = "nvidia,tegra132-ccplex-clk";
		reg = <0x00 0x70040000 0x00 0x1000>;
		status = "okay";
		#clock-cells = <0x01>;
		phandle = <0x2b>;
	};

	clock@70040084 {
		compatible = "nvidia,tegra132-dfll";
		reg = <0x00 0x70040084 0x00 0x100 0x00 0x70110000 0x00 0x100 0x00 0x70110100 0x00 0x100 0x00 0x70110200 0x00 0x100>;
		interrupts = <0x00 0x3e 0x04>;
		clocks = <0x03 0x109 0x03 0x108 0x03 0x2f>;
		clock-names = "soc", "ref", "i2c";
		resets = <0x03 0xc0>;
		reset-names = "dvco";
		#clock-cells = <0x00>;
		clock-output-names = "dfllCPU_out";
		nvidia,sample-rate = <0x30d4>;
		nvidia,droop-ctrl = <0xf00>;
		nvidia,force-mode = <0x01>;
		nvidia,cf = <0x0a>;
		nvidia,ci = <0x00>;
		nvidia,cg = <0x02>;
		status = "okay";
		vdd-cpu-supply = <0x1b>;
		nvidia,i2c-fs-rate = <0x61a80>;
		phandle = <0x2c>;
	};

	usb@70090000 {
		compatible = "nvidia,tegra132-xusb", "nvidia,tegra124-xusb";
		reg = <0x00 0x70090000 0x00 0x8000 0x00 0x70098000 0x00 0x1000 0x00 0x70099000 0x00 0x1000>;
		reg-names = "hcd", "fpci", "ipfs";
		interrupts = <0x00 0x27 0x04 0x00 0x28 0x04>;
		clocks = <0x03 0x59 0x03 0xfc 0x03 0xfd 0x03 0x9c 0x03 0x138 0x03 0xff 0x03 0x102 0x03 0xfe 0x03 0xdf 0x03 0xc9 0x03 0xe7>;
		clock-names = "xusb_host", "xusb_host_src", "xusb_falcon_src", "xusb_ss", "xusb_ss_div2", "xusb_ss_src", "xusb_hs_src", "xusb_fs_src", "pll_u_480m", "clk_m", "pll_e";
		resets = <0x03 0x59 0x03 0x9c 0x03 0x8f>;
		reset-names = "xusb_host", "xusb_ss", "xusb_src";
		nvidia,xusb-padctl = <0x1c>;
		status = "disabled";
	};

	padctl@7009f000 {
		compatible = "nvidia,tegra132-xusb-padctl", "nvidia,tegra124-xusb-padctl";
		reg = <0x00 0x7009f000 0x00 0x1000>;
		resets = <0x03 0x8e>;
		reset-names = "padctl";
		status = "okay";
		avdd-pll-utmip-supply = <0x17>;
		avdd-pll-erefe-supply = <0x1d>;
		avdd-pex-pll-supply = <0x1d>;
		hvdd-pex-pll-e-supply = <0x1e>;
		phandle = <0x1c>;

		pads {

			usb2 {
				status = "okay";

				lanes {

					usb2-0 {
						status = "okay";
						#phy-cells = <0x00>;
						nvidia,function = "snps";
					};

					usb2-1 {
						status = "disabled";
						#phy-cells = <0x00>;
					};

					usb2-2 {
						status = "disabled";
						#phy-cells = <0x00>;
					};
				};
			};

			ulpi {
				status = "disabled";

				lanes {

					ulpi-0 {
						status = "disabled";
						#phy-cells = <0x00>;
					};
				};
			};

			hsic {
				status = "disabled";

				lanes {

					hsic-0 {
						status = "disabled";
						#phy-cells = <0x00>;
					};

					hsic-1 {
						status = "disabled";
						#phy-cells = <0x00>;
					};
				};
			};

			pcie {
				status = "disabled";

				lanes {

					pcie-0 {
						status = "disabled";
						#phy-cells = <0x00>;
					};

					pcie-1 {
						status = "disabled";
						#phy-cells = <0x00>;
					};

					pcie-2 {
						status = "disabled";
						#phy-cells = <0x00>;
					};

					pcie-3 {
						status = "disabled";
						#phy-cells = <0x00>;
					};

					pcie-4 {
						status = "disabled";
						#phy-cells = <0x00>;
					};
				};
			};

			sata {
				status = "disabled";

				lanes {

					sata-0 {
						status = "disabled";
						#phy-cells = <0x00>;
					};
				};
			};
		};

		ports {

			usb2-0 {
				status = "okay";
				vbus-supply = <0x1f>;
				mode = "otg";
				usb-role-switch;
			};

			usb2-1 {
				status = "disabled";
			};

			usb2-2 {
				status = "disabled";
			};

			hsic-0 {
				status = "disabled";
			};

			hsic-1 {
				status = "disabled";
			};

			usb3-0 {
				status = "disabled";
			};

			usb3-1 {
				status = "disabled";
			};
		};
	};

	mmc@700b0000 {
		compatible = "nvidia,tegra124-sdhci";
		reg = <0x00 0x700b0000 0x00 0x200>;
		interrupts = <0x00 0x0e 0x04>;
		clocks = <0x03 0x0e>;
		clock-names = "sdhci";
		resets = <0x03 0x0e>;
		reset-names = "sdhci";
		status = "okay";
		bus-width = <0x04>;
		sd-uhs-sdr104;
		nvidia,only-1-8v;
		non-removable;
		mmc-pwrseq = <0x20>;
		vqmmc-supply = <0x17>;
		#address-cells = <0x01>;
		#size-cells = <0x00>;

		wifi@1 {
			compatible = "brcm,bcm4354-fmac", "brcm,bcm4329-fmac";
			reg = <0x01>;
			interrupt-parent = <0x0a>;
			interrupts = <0xa5 0x04>;
			interrupt-names = "host-wake";
		};
	};

	mmc@700b0200 {
		compatible = "nvidia,tegra124-sdhci";
		reg = <0x00 0x700b0200 0x00 0x200>;
		interrupts = <0x00 0x0f 0x04>;
		clocks = <0x03 0x09>;
		clock-names = "sdhci";
		resets = <0x03 0x09>;
		reset-names = "sdhci";
		status = "disabled";
	};

	mmc@700b0400 {
		compatible = "nvidia,tegra124-sdhci";
		reg = <0x00 0x700b0400 0x00 0x200>;
		interrupts = <0x00 0x13 0x04>;
		clocks = <0x03 0x45>;
		clock-names = "sdhci";
		resets = <0x03 0x45>;
		reset-names = "sdhci";
		status = "disabled";
	};

	mmc@700b0600 {
		compatible = "nvidia,tegra124-sdhci";
		reg = <0x00 0x700b0600 0x00 0x200>;
		interrupts = <0x00 0x1f 0x04>;
		clocks = <0x03 0x0f>;
		clock-names = "sdhci";
		resets = <0x03 0x0f>;
		reset-names = "sdhci";
		status = "okay";
		bus-width = <0x08>;
		mmc-hs200-1_8v;
		nvidia,only-1-8v;
		non-removable;
		vqmmc-supply = <0x17>;
	};

	thermal-sensor@700e2000 {
		compatible = "nvidia,tegra132-soctherm";
		reg = <0x00 0x700e2000 0x00 0x600 0x00 0x70040000 0x00 0x200>;
		reg-names = "soctherm-reg", "ccroc-reg";
		interrupts = <0x00 0x30 0x04 0x00 0x33 0x04>;
		interrupt-names = "thermal", "edp";
		clocks = <0x03 0x64 0x03 0x4e>;
		clock-names = "tsensor", "soctherm";
		resets = <0x03 0x4e>;
		reset-names = "soctherm";
		#thermal-sensor-cells = <0x01>;
		phandle = <0x21>;

		throttle-cfgs {

			heavy {
				nvidia,priority = <0x64>;
				nvidia,cpu-throt-level = <0x03>;
				#cooling-cells = <0x02>;
				phandle = <0x23>;
			};
		};
	};

	mipi@700e3000 {
		compatible = "nvidia,tegra132-mipi";
		reg = <0x00 0x700e3000 0x00 0x100>;
		clocks = <0x03 0x38>;
		#nvidia,mipi-calibrate-cells = <0x01>;
		phandle = <0x05>;
	};

	thermal-zones {

		cpu-thermal {
			polling-delay-passive = <0x3e8>;
			polling-delay = <0x00>;
			thermal-sensors = <0x21 0x00>;

			trips {

				cpu_shutdown_trip {
					temperature = <0x17318>;
					hysteresis = <0x3e8>;
					type = "critical";
				};

				throttle-trip {
					temperature = <0x14438>;
					hysteresis = <0x3e8>;
					type = "passive";
					phandle = <0x22>;
				};

				cpu_shutdown_warn {
					temperature = <0x16b48>;
					hysteresis = <0x00>;
					type = "hot";
				};
			};

			cooling-maps {

				map0 {
					trip = <0x22>;
					cooling-device = <0x23 0x01 0x01>;
				};
			};
		};

		mem-thermal {
			polling-delay-passive = <0x00>;
			polling-delay = <0x00>;
			thermal-sensors = <0x21 0x01>;

			trips {

				mem_shutdown_trip {
					temperature = <0x17318>;
					hysteresis = <0x3e8>;
					type = "critical";
				};

				mem_throttle_trip {
					temperature = <0x14438>;
					hysteresis = <0x3e8>;
					type = "passive";
				};

				mem_shutdown_warn {
					temperature = <0x16b48>;
					hysteresis = <0x00>;
					type = "hot";
				};
			};

			cooling-maps {
			};
		};

		gpu-thermal {
			polling-delay-passive = <0x3e8>;
			polling-delay = <0x00>;
			thermal-sensors = <0x21 0x02>;

			trips {

				gpu_shutdown_trip {
					temperature = <0x17318>;
					hysteresis = <0x3e8>;
					type = "critical";
				};

				throttle-trip {
					temperature = <0x14438>;
					hysteresis = <0x3e8>;
					type = "passive";
					phandle = <0x24>;
				};

				gpu_shutdown_warn {
					temperature = <0x16b48>;
					hysteresis = <0x00>;
					type = "hot";
				};
			};

			cooling-maps {

				map0 {
					trip = <0x24>;
					cooling-device = <0x23 0x01 0x01>;
				};
			};
		};

		pllx-thermal {
			polling-delay-passive = <0x00>;
			polling-delay = <0x00>;
			thermal-sensors = <0x21 0x03>;

			trips {

				pllx_shutdown_trip {
					temperature = <0x17318>;
					hysteresis = <0x3e8>;
					type = "critical";
				};

				pllx_throttle_trip {
					temperature = <0x14438>;
					hysteresis = <0x3e8>;
					type = "passive";
				};

				pllx_shutdown_warn {
					temperature = <0x16b48>;
					hysteresis = <0x00>;
					type = "hot";
				};
			};

			cooling-maps {
			};
		};
	};

	ahub@70300000 {
		compatible = "nvidia,tegra124-ahub";
		reg = <0x00 0x70300000 0x00 0x200 0x00 0x70300800 0x00 0x800 0x00 0x70300200 0x00 0x600>;
		interrupts = <0x00 0x67 0x04>;
		clocks = <0x03 0x6a 0x03 0x6b>;
		clock-names = "d_audio", "apbif";
		resets = <0x03 0x6a 0x03 0x6b 0x03 0x1e 0x03 0x0b 0x03 0x12 0x03 0x65 0x03 0x66 0x03 0x6c 0x03 0x6d 0x03 0x6e 0x03 0x0a 0x03 0x99 0x03 0xb9 0x03 0x9a 0x03 0xb4 0x03 0xba 0x03 0xbb 0x03 0xbc 0x03 0xbd 0x03 0xbe 0x03 0xbf>;
		reset-names = "d_audio", "apbif", "i2s0", "i2s1", "i2s2", "i2s3", "i2s4", "dam0", "dam1", "dam2", "spdif", "amx", "amx1", "adx", "adx1", "afc0", "afc1", "afc2", "afc3", "afc4", "afc5";
		dmas = <0x11 0x01 0x11 0x01 0x11 0x02 0x11 0x02 0x11 0x03 0x11 0x03 0x11 0x04 0x11 0x04 0x11 0x06 0x11 0x06 0x11 0x07 0x11 0x07 0x11 0x0c 0x11 0x0c 0x11 0x0d 0x11 0x0d 0x11 0x0e 0x11 0x0e 0x11 0x1d 0x11 0x1d>;
		dma-names = "rx0", "tx0", "rx1", "tx1", "rx2", "tx2", "rx3", "tx3", "rx4", "tx4", "rx5", "tx5", "rx6", "tx6", "rx7", "tx7", "rx8", "tx8", "rx9", "tx9";
		ranges;
		#address-cells = <0x02>;
		#size-cells = <0x02>;

		i2s@70301000 {
			compatible = "nvidia,tegra124-i2s";
			reg = <0x00 0x70301000 0x00 0x100>;
			nvidia,ahub-cif-ids = <0x04 0x04>;
			clocks = <0x03 0x1e>;
			clock-names = "i2s";
			resets = <0x03 0x1e>;
			reset-names = "i2s";
			status = "okay";
		};

		i2s@70301100 {
			compatible = "nvidia,tegra124-i2s";
			reg = <0x00 0x70301100 0x00 0x100>;
			nvidia,ahub-cif-ids = <0x05 0x05>;
			clocks = <0x03 0x0b>;
			clock-names = "i2s";
			resets = <0x03 0x0b>;
			reset-names = "i2s";
			status = "okay";
		};

		i2s@70301200 {
			compatible = "nvidia,tegra124-i2s";
			reg = <0x00 0x70301200 0x00 0x100>;
			nvidia,ahub-cif-ids = <0x06 0x06>;
			clocks = <0x03 0x12>;
			clock-names = "i2s";
			resets = <0x03 0x12>;
			reset-names = "i2s";
			status = "okay";
		};

		i2s@70301300 {
			compatible = "nvidia,tegra124-i2s";
			reg = <0x00 0x70301300 0x00 0x100>;
			nvidia,ahub-cif-ids = <0x07 0x07>;
			clocks = <0x03 0x65>;
			clock-names = "i2s";
			resets = <0x03 0x65>;
			reset-names = "i2s";
			status = "okay";
		};

		i2s@70301400 {
			compatible = "nvidia,tegra124-i2s";
			reg = <0x00 0x70301400 0x00 0x100>;
			nvidia,ahub-cif-ids = <0x08 0x08>;
			clocks = <0x03 0x66>;
			clock-names = "i2s";
			resets = <0x03 0x66>;
			reset-names = "i2s";
			status = "disabled";
		};
	};

	usb@7d000000 {
		compatible = "nvidia,tegra124-udc";
		reg = <0x00 0x7d000000 0x00 0x4000>;
		interrupts = <0x00 0x14 0x04>;
		phy_type = "utmi";
		clocks = <0x03 0x16>;
		clock-names = "usb";
		resets = <0x03 0x16>;
		reset-names = "usb";
		nvidia,phy = <0x25>;
		status = "okay";
		dr_mode = "otg";
		extcon = <0x26 0x27>;
		vbus-supply = <0x1f>;
	};

	usb-phy@7d000000 {
		compatible = "nvidia,tegra124-usb-phy", "nvidia,tegra30-usb-phy";
		reg = <0x00 0x7d000000 0x00 0x4000 0x00 0x7d000000 0x00 0x4000>;
		interrupts = <0x00 0x14 0x04>;
		phy_type = "utmi";
		clocks = <0x03 0x16 0x03 0xde 0x03 0x16>;
		clock-names = "reg", "pll_u", "utmi-pads";
		resets = <0x03 0x16 0x03 0x16>;
		reset-names = "usb", "utmi-pads";
		#phy-cells = <0x00>;
		nvidia,hssync-start-delay = <0x00>;
		nvidia,idle-wait-delay = <0x11>;
		nvidia,elastic-limit = <0x10>;
		nvidia,term-range-adj = <0x06>;
		nvidia,xcvr-setup = <0x09>;
		nvidia,xcvr-lsfslew = <0x00>;
		nvidia,xcvr-lsrslew = <0x03>;
		nvidia,hssquelch-level = <0x02>;
		nvidia,hsdiscon-level = <0x05>;
		nvidia,xcvr-hsslew = <0x0c>;
		nvidia,has-utmi-pad-registers;
		nvidia,pmc = <0x28 0x00>;
		status = "okay";
		dr_mode = "otg";
		vbus-supply = <0x1e>;
		phandle = <0x25>;
	};

	usb@7d004000 {
		compatible = "nvidia,tegra124-ehci", "nvidia,tegra30-ehci";
		reg = <0x00 0x7d004000 0x00 0x4000>;
		interrupts = <0x00 0x15 0x04>;
		phy_type = "utmi";
		clocks = <0x03 0x3a>;
		clock-names = "usb";
		resets = <0x03 0x3a>;
		reset-names = "usb";
		nvidia,phy = <0x29>;
		status = "disabled";
	};

	usb-phy@7d004000 {
		compatible = "nvidia,tegra124-usb-phy", "nvidia,tegra30-usb-phy";
		reg = <0x00 0x7d004000 0x00 0x4000 0x00 0x7d000000 0x00 0x4000>;
		interrupts = <0x00 0x15 0x04>;
		phy_type = "utmi";
		clocks = <0x03 0x3a 0x03 0xde 0x03 0x16>;
		clock-names = "reg", "pll_u", "utmi-pads";
		resets = <0x03 0x3a 0x03 0x16>;
		reset-names = "usb", "utmi-pads";
		#phy-cells = <0x00>;
		nvidia,hssync-start-delay = <0x00>;
		nvidia,idle-wait-delay = <0x11>;
		nvidia,elastic-limit = <0x10>;
		nvidia,term-range-adj = <0x06>;
		nvidia,xcvr-setup = <0x09>;
		nvidia,xcvr-lsfslew = <0x00>;
		nvidia,xcvr-lsrslew = <0x03>;
		nvidia,hssquelch-level = <0x02>;
		nvidia,hsdiscon-level = <0x05>;
		nvidia,xcvr-hsslew = <0x0c>;
		nvidia,pmc = <0x28 0x01>;
		status = "disabled";
		phandle = <0x29>;
	};

	usb@7d008000 {
		compatible = "nvidia,tegra124-ehci", "nvidia,tegra30-ehci";
		reg = <0x00 0x7d008000 0x00 0x4000>;
		interrupts = <0x00 0x61 0x04>;
		phy_type = "utmi";
		clocks = <0x03 0x3b>;
		clock-names = "usb";
		resets = <0x03 0x3b>;
		reset-names = "usb";
		nvidia,phy = <0x2a>;
		status = "disabled";
	};

	usb-phy@7d008000 {
		compatible = "nvidia,tegra124-usb-phy", "nvidia,tegra30-usb-phy";
		reg = <0x00 0x7d008000 0x00 0x4000 0x00 0x7d000000 0x00 0x4000>;
		interrupts = <0x00 0x61 0x04>;
		phy_type = "utmi";
		clocks = <0x03 0x3b 0x03 0xde 0x03 0x16>;
		clock-names = "reg", "pll_u", "utmi-pads";
		resets = <0x03 0x3b 0x03 0x16>;
		reset-names = "usb", "utmi-pads";
		#phy-cells = <0x00>;
		nvidia,hssync-start-delay = <0x00>;
		nvidia,idle-wait-delay = <0x11>;
		nvidia,elastic-limit = <0x10>;
		nvidia,term-range-adj = <0x06>;
		nvidia,xcvr-setup = <0x09>;
		nvidia,xcvr-lsfslew = <0x00>;
		nvidia,xcvr-lsrslew = <0x03>;
		nvidia,hssquelch-level = <0x02>;
		nvidia,hsdiscon-level = <0x05>;
		nvidia,xcvr-hsslew = <0x0c>;
		nvidia,pmc = <0x28 0x02>;
		status = "disabled";
		phandle = <0x2a>;
	};

	cpus {
		#address-cells = <0x01>;
		#size-cells = <0x00>;

		cpu@0 {
			device_type = "cpu";
			compatible = "nvidia,tegra132-denver";
			reg = <0x00>;
			enable-method = "spin-table";
			cpu-release-addr = <0x8000fff8>;
			clocks = <0x2b 0x01 0x2b 0x02 0x03 0xd3 0x2c>;
			clock-names = "cpu_g", "pll_x", "pll_p", "dfll";
			clock-latency = <0x493e0>;
			vdd-cpu-supply = <0x1b>;
		};

		cpu@1 {
			device_type = "cpu";
			compatible = "nvidia,tegra132-denver";
			reg = <0x01>;
			enable-method = "spin-table";
			cpu-release-addr = <0x8000fff8>;
		};
	};

	timer {
		compatible = "arm,armv7-timer";
		interrupts = <0x01 0x0d 0xf08 0x01 0x0e 0xf08 0x01 0x0b 0xf08 0x01 0x0a 0xf08>;
		interrupt-parent = <0x02>;
	};

	aliases {
		i2c0 = "/i2c@7000c000";
		i2c1 = "/i2c@7000c400";
		i2c2 = "/i2c@7000c500";
		i2c4 = "/i2c@7000d000";
		spi2 = "/spi@7000d800";
		spi3 = "/spi@7000da00";
		spi4 = "/spi@7000dc00";
		rtc0 = "/i2c@7000d000/tps65913@58/rtc";
		rtc1 = "/rtc@7000e000";
		mmc0 = "/mmc@700b0600";
		mmc1 = "/mmc@700b0000";
	};

	chosen {
		stdout-path = "/serial@70006000:115200n8";
		#address-cells = <0x02>;
		#size-cells = <0x02>;
		ranges;

		framebuffer@ac001000 {
			compatible = "simple-framebuffer";
			reg = <0x00 0xac001000 0x00 0xc20000>;
			width = <0x600>;
			height = <0x800>;
			stride = <0x1800>;
			format = "a8b8g8r8";
			clocks = <0x03 0x1b 0x03 0x30 0x03 0x52>;
			dsi-supply = <0x06>;
			lcd-supply = <0x08>;
			io-supply = <0x09>;
		};
	};

	memory@80000000 {
		device_type = "memory";
		reg = <0x00 0x80000000 0x00 0x80000000>;
	};

	reserved-memory {
		#address-cells = <0x02>;
		#size-cells = <0x02>;
		ranges;

		framebuffer@ac001000 {
			reg = <0x00 0xac001000 0x00 0xc20000>;
			no-map;
		};
	};

	pwrseq-wifi {
		compatible = "mmc-pwrseq-simple";
		reset-gpios = <0x0a 0xbf 0x01>;
		post-power-on-delay-ms = <0x12c>;
		power-off-delay-us = <0x12c>;
		phandle = <0x20>;
	};

	extcon-usb-gpio {
		compatible = "linux,extcon-usb-gpio";
		id-gpio = <0x0a 0xb2 0x00>;
		phandle = <0x27>;
	};

	clock-32k {
		compatible = "fixed-clock";
		clock-frequency = <0x8000>;
		#clock-cells = <0x00>;
		phandle = <0x19>;
	};

	gpio-keys {
		compatible = "gpio-keys";

		power {
			label = "Power";
			gpios = <0x0a 0x80 0x01>;
			linux,code = <0x74>;
			debounce-interval = <0x14>;
			wakeup-source;
		};

		volume_down {
			label = "Volume Down";
			gpios = <0x0a 0x85 0x01>;
			linux,code = <0x72>;
			debounce-interval = <0x14>;
		};

		volume_up {
			label = "Volume Up";
			gpios = <0x0a 0xaa 0x01>;
			linux,code = <0x73>;
			debounce-interval = <0x14>;
		};
	};

	vibrator {
		compatible = "gpio-vibrator";
		enable-gpios = <0x0a 0xa3 0x00>;
		vcc-supply = <0x16>;
	};

	regulator-vdd-battery {
		compatible = "regulator-fixed";
		regulator-name = "vdd-battery";
		regulator-always-on;
		regulator-boot-on;
		phandle = <0x16>;
	};

	regulator-avdd-lcd {
		compatible = "regulator-fixed";
		regulator-name = "avdd-lcd";
		gpio = <0x0a 0x88 0x00>;
		enable-active-high;
		regulator-boot-on;
		vin-supply = <0x16>;
		phandle = <0x08>;
	};

	regulator-iovdd-lcd {
		compatible = "regulator-fixed";
		regulator-name = "iovdd-lcd";
		regulator-min-microvolt = <0x1b7740>;
		regulator-max-microvolt = <0x1b7740>;
		gpio = <0x0a 0x82 0x00>;
		enable-active-high;
		regulator-boot-on;
		vin-supply = <0x17>;
		phandle = <0x09>;
	};
};
